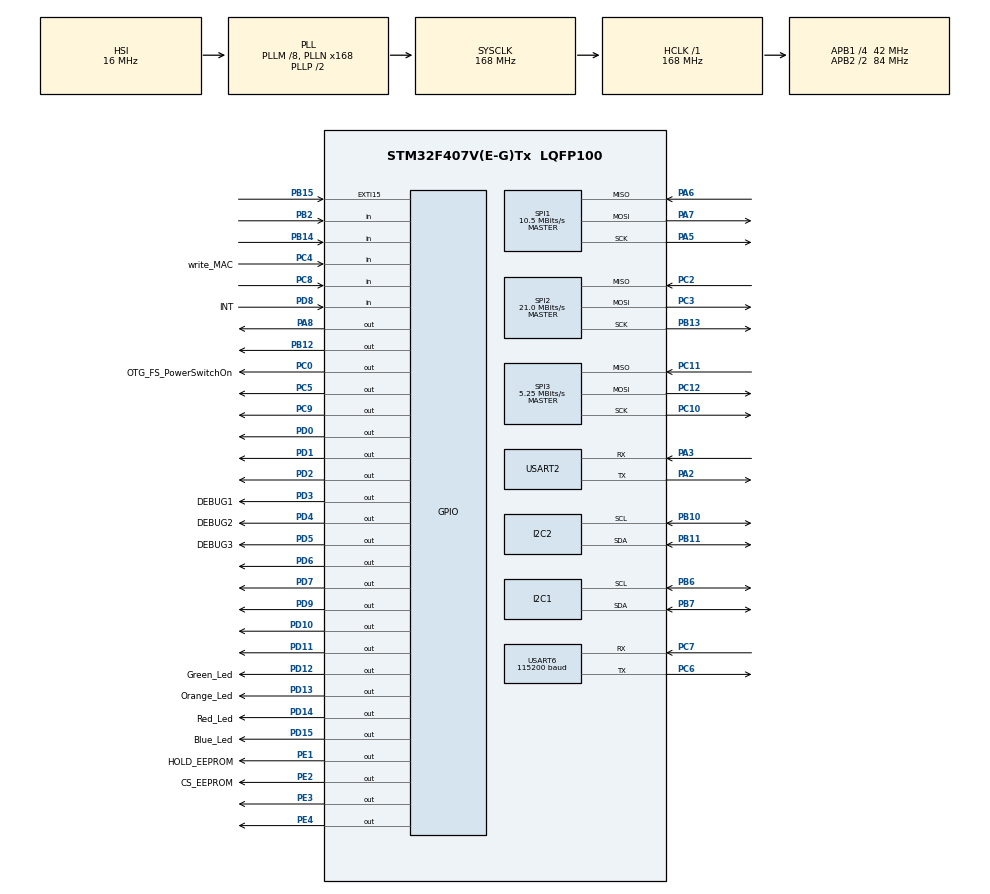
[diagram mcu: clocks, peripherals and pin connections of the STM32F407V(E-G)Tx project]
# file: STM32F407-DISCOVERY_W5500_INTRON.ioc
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Dma.Request0=USART6_TX
Dma.Request1=SPI1_TX
Dma.Request2=SPI1_RX
Dma.SPI1_RX.2.Direction=DMA_PERIPH_TO_MEMORY
Dma.SPI1_RX.2.FIFOMode=DMA_FIFOMODE_DISABLE
Dma.SPI1_RX.2.Instance=DMA2_Stream0
Dma.SPI1_RX.2.MemDataAlignment=DMA_MDATAALIGN_BYTE
Dma.SPI1_RX.2.MemInc=DMA_MINC_ENABLE
Dma.SPI1_RX.2.Mode=DMA_NORMAL
Dma.SPI1_RX.2.PeriphDataAlignment=DMA_PDATAALIGN_BYTE
Dma.SPI1_RX.2.PeriphInc=DMA_PINC_DISABLE
Dma.SPI1_RX.2.Priority=DMA_PRIORITY_LOW
Dma.SPI1_TX.1.Direction=DMA_MEMORY_TO_PERIPH
Dma.SPI1_TX.1.FIFOMode=DMA_FIFOMODE_DISABLE
Dma.SPI1_TX.1.Instance=DMA2_Stream3
Dma.SPI1_TX.1.MemDataAlignment=DMA_MDATAALIGN_BYTE
Dma.SPI1_TX.1.MemInc=DMA_MINC_ENABLE
Dma.SPI1_TX.1.Mode=DMA_NORMAL
Dma.SPI1_TX.1.PeriphDataAlignment=DMA_PDATAALIGN_BYTE
Dma.SPI1_TX.1.PeriphInc=DMA_PINC_DISABLE
Dma.SPI1_TX.1.Priority=DMA_PRIORITY_LOW
Dma.USART6_TX.0.Direction=DMA_MEMORY_TO_PERIPH
Dma.USART6_TX.0.FIFOMode=DMA_FIFOMODE_DISABLE
Dma.USART6_TX.0.Instance=DMA2_Stream6
Dma.USART6_TX.0.MemDataAlignment=DMA_MDATAALIGN_BYTE
Dma.USART6_TX.0.MemInc=DMA_MINC_ENABLE
Dma.USART6_TX.0.Mode=DMA_NORMAL
Dma.USART6_TX.0.PeriphDataAlignment=DMA_PDATAALIGN_BYTE
Dma.USART6_TX.0.PeriphInc=DMA_PINC_DISABLE
Dma.USART6_TX.0.Priority=DMA_PRIORITY_HIGH
FATFS._FS_EXFAT=1
FATFS._FS_NOFSINFO=3
FATFS._MAX_SS=4096
FATFS._MULTI_PARTITION=1
FATFS._USE_CHMOD=1
FATFS._USE_EXPAND=1
FATFS._USE_FIND=1
FATFS._USE_FORWARD=1
FATFS._USE_LABEL=1
FATFS._USE_LFN=1
FATFS._USE_TRIM=1
I2C1.DutyCycle=I2C_DUTYCYCLE_2
I2C1.I2C_Mode=I2C_Fast
IWDG.Prescaler=IWDG_PRESCALER_128
IWDG.Reload=2000
Mcu.Family=STM32F4
Mcu.Name=STM32F407V(E-G)Tx
Mcu.Package=LQFP100
NVIC.DMA2_Stream0_IRQn=true\:0\:0\:false\:false\:true\:true\:true
NVIC.DMA2_Stream3_IRQn=true\:0\:0\:false\:false\:true\:true\:true
NVIC.DMA2_Stream6_IRQn=true\:0\:0\:false\:false\:true\:false\:true
NVIC.EXTI15_10_IRQn=true\:0\:0\:false\:false\:true\:true\:true
NVIC.PriorityGroup=NVIC_PRIORITYGROUP_4
NVIC.SPI3_IRQn=true\:0\:0\:false\:false\:true\:true\:true
NVIC.USART2_IRQn=true\:0\:0\:false\:false\:true\:true\:true
NVIC.USART6_IRQn=true\:0\:0\:false\:false\:true\:true\:true
PA13.GPIO_Label=SWDIO
PA13.Mode=Serial_Wire
PA13.Signal=SYS_JTMS-SWDIO
PA14.GPIO_Label=SWCLK
PA14.Mode=Serial_Wire
PA14.Signal=SYS_JTCK-SWCLK
PA2.Mode=Asynchronous
PA2.Signal=USART2_TX
PA3.Mode=Asynchronous
PA3.Signal=USART2_RX
PA5.Mode=Full_Duplex_Master
PA5.Signal=SPI1_SCK
PA6.Mode=Full_Duplex_Master
PA6.Signal=SPI1_MISO
PA7.Mode=Full_Duplex_Master
PA7.Signal=SPI1_MOSI
PA8.GPIO_Speed=GPIO_SPEED_FREQ_VERY_HIGH
PA8.PinState=GPIO_PIN_SET
PA8.Signal=GPIO_Output
PB10.Mode=I2C
PB10.Signal=I2C2_SCL
PB11.Mode=I2C
PB11.Signal=I2C2_SDA
PB12.Signal=GPIO_Output
PB13.GPIO_PuPd=GPIO_PULLUP
PB13.Mode=Full_Duplex_Master
PB13.Signal=SPI2_SCK
PB14.GPIO_PuPd=GPIO_PULLDOWN
PB14.Signal=GPIO_Input
PB15.Signal=GPXTI15
PB2.Signal=GPIO_Input
PB6.Mode=I2C
PB6.Signal=I2C1_SCL
PB7.Mode=I2C
PB7.Signal=I2C1_SDA
PC0.GPIO_Label=OTG_FS_PowerSwitchOn
PC0.GPIO_PuPd=GPIO_NOPULL
PC0.GPIO_Speed=GPIO_SPEED_FREQ_LOW
PC0.PinState=GPIO_PIN_SET
PC0.Signal=GPIO_Output
PC10.GPIO_PuPd=GPIO_NOPULL
PC10.Mode=Full_Duplex_Master
PC10.Signal=SPI3_SCK
PC11.GPIO_PuPd=GPIO_PULLUP
PC11.Mode=Full_Duplex_Master
PC11.Signal=SPI3_MISO
PC12.GPIO_PuPd=GPIO_PULLUP
PC12.Mode=Full_Duplex_Master
PC12.Signal=SPI3_MOSI
PC2.GPIO_PuPd=GPIO_NOPULL
PC2.Mode=Full_Duplex_Master
PC2.Signal=SPI2_MISO
PC3.GPIO_PuPd=GPIO_PULLUP
PC3.Mode=Full_Duplex_Master
PC3.Signal=SPI2_MOSI
PC4.GPIO_Label=write_MAC
PC4.Signal=GPIO_Input
PC5.Signal=GPIO_Output
PC6.Mode=Asynchronous
PC6.Signal=USART6_TX
PC7.Mode=Asynchronous
PC7.Signal=USART6_RX
PC8.Signal=GPIO_Input
PC9.GPIO_Speed=GPIO_SPEED_FREQ_VERY_HIGH
PC9.PinState=GPIO_PIN_SET
PC9.Signal=GPIO_Output
PD0.GPIO_Speed=GPIO_SPEED_FREQ_VERY_HIGH
PD0.Signal=GPIO_Output
PD1.GPIO_Speed=GPIO_SPEED_FREQ_VERY_HIGH
PD1.Signal=GPIO_Output
PD10.GPIO_Speed=GPIO_SPEED_FREQ_VERY_HIGH
PD10.PinState=GPIO_PIN_RESET
PD10.Signal=GPIO_Output
PD11.GPIO_Speed=GPIO_SPEED_FREQ_VERY_HIGH
PD11.PinState=GPIO_PIN_SET
PD11.Signal=GPIO_Output
PD12.GPIO_Label=Green_Led
PD12.GPIO_PuPd=GPIO_NOPULL
PD12.GPIO_Speed=GPIO_SPEED_FREQ_VERY_HIGH
PD12.Signal=GPIO_Output
PD13.GPIO_Label=Orange_Led
PD13.GPIO_PuPd=GPIO_NOPULL
PD13.GPIO_Speed=GPIO_SPEED_FREQ_VERY_HIGH
PD13.Signal=GPIO_Output
PD14.GPIO_Label=Red_Led
PD14.GPIO_PuPd=GPIO_NOPULL
PD14.GPIO_Speed=GPIO_SPEED_FREQ_VERY_HIGH
PD14.Signal=GPIO_Output
PD15.GPIO_Label=Blue_Led
PD15.GPIO_PuPd=GPIO_NOPULL
PD15.GPIO_Speed=GPIO_SPEED_FREQ_VERY_HIGH
PD15.Signal=GPIO_Output
PD2.GPIO_PuPd=GPIO_PULLUP
PD2.GPIO_Speed=GPIO_SPEED_FREQ_MEDIUM
PD2.PinState=GPIO_PIN_SET
PD2.Signal=GPIO_Output
PD3.GPIO_Label=DEBUG1
PD3.GPIO_Speed=GPIO_SPEED_FREQ_VERY_HIGH
PD3.Signal=GPIO_Output
PD4.GPIO_Label=DEBUG2
PD4.GPIO_Speed=GPIO_SPEED_FREQ_VERY_HIGH
PD4.Signal=GPIO_Output
PD5.GPIO_Label=DEBUG3
PD5.GPIO_Speed=GPIO_SPEED_FREQ_VERY_HIGH
PD5.Signal=GPIO_Output
PD6.Signal=GPIO_Output
PD7.GPIO_Speed=GPIO_SPEED_FREQ_VERY_HIGH
PD7.Signal=GPIO_Output
PD8.GPIO_Label=INT
PD8.Signal=GPIO_Input
PD9.GPIO_Speed=GPIO_SPEED_FREQ_VERY_HIGH
PD9.Signal=GPIO_Output
PE1.GPIO_Label=HOLD_EEPROM
PE1.PinState=GPIO_PIN_SET
PE1.Signal=GPIO_Output
PE2.GPIO_Label=CS_EEPROM
PE2.GPIO_PuPd=GPIO_PULLUP
PE2.GPIO_Speed=GPIO_SPEED_FREQ_MEDIUM
PE2.PinState=GPIO_PIN_SET
PE2.Signal=GPIO_Output
PE3.Signal=GPIO_Output
PE4.Signal=GPIO_Output
PH0-OSC_IN.GPIO_Label=PH0-OSC_IN
PH0-OSC_IN.Mode=HSE-External-Oscillator
PH0-OSC_IN.Signal=RCC_OSC_IN
PH1-OSC_OUT.GPIO_Label=PH1-OSC_OUT
PH1-OSC_OUT.Mode=HSE-External-Oscillator
PH1-OSC_OUT.Signal=RCC_OSC_OUT
ProjectManager.HeapSize=0x2000
ProjectManager.StackSize=0x4000
ProjectManager.TargetToolchain=STM32CubeIDE
RCC.48MHZClocksFreq_Value=48000000
RCC.AHBFreq_Value=168000000
RCC.APB1CLKDivider=RCC_HCLK_DIV4
RCC.APB1Freq_Value=42000000
RCC.APB1TimFreq_Value=84000000
RCC.APB2CLKDivider=RCC_HCLK_DIV2
RCC.APB2Freq_Value=84000000
RCC.APB2TimFreq_Value=168000000
RCC.CortexFreq_Value=168000000
RCC.HCLKFreq_Value=168000000
RCC.HSE_VALUE=5000000
RCC.HSI_VALUE=16000000
RCC.LSE_VALUE=32768
RCC.PLLM=8
RCC.PLLN=168
RCC.PLLQ=7
RCC.SYSCLKFreq_VALUE=168000000
RCC.SYSCLKSource=RCC_SYSCLKSOURCE_PLLCLK
RCC.VCOOutputFreq_Value=336000000
RTC.Date=9
RTC.Month=RTC_MONTH_MAY
RTC.Year=23
SPI1.BaudRatePrescaler=SPI_BAUDRATEPRESCALER_8
SPI1.CalculateBaudRate=10.5 MBits/s
SPI1.Direction=SPI_DIRECTION_2LINES
SPI1.Mode=SPI_MODE_MASTER
SPI1.VirtualType=VM_MASTER
SPI2.BaudRatePrescaler=SPI_BAUDRATEPRESCALER_2
SPI2.CLKPhase=SPI_PHASE_2EDGE
SPI2.CLKPolarity=SPI_POLARITY_LOW
SPI2.CalculateBaudRate=21.0 MBits/s
SPI2.Direction=SPI_DIRECTION_2LINES
SPI2.Mode=SPI_MODE_MASTER
SPI2.VirtualType=VM_MASTER
SPI3.BaudRatePrescaler=SPI_BAUDRATEPRESCALER_8
SPI3.CLKPhase=SPI_PHASE_1EDGE
SPI3.CLKPolarity=SPI_POLARITY_LOW
SPI3.CRCCalculation=SPI_CRCCALCULATION_DISABLE
SPI3.CalculateBaudRate=5.25 MBits/s
SPI3.DataSize=SPI_DATASIZE_8BIT
SPI3.Direction=SPI_DIRECTION_2LINES
SPI3.Mode=SPI_MODE_MASTER
SPI3.VirtualType=VM_MASTER
USART2.VirtualMode=VM_ASYNC
USART6.BaudRate=115200
USART6.VirtualMode=VM_ASYNC
VP_CRC_VS_CRC.Mode=CRC_Activate
VP_FATFS_VS_Generic.Mode=User_defined
VP_IWDG_VS_IWDG.Mode=IWDG_Activate
VP_RNG_VS_RNG.Mode=RNG_Activate
VP_RTC_VS_RTC_Activate.Mode=RTC_Enabled
VP_RTC_VS_RTC_Calendar.Mode=RTC_Calendar
VP_wolfSSL.I-CUBE-wolfSSL_VS_wolfSSLJjwolfSSL_5.6.0_5.6.0.Mode=wolfSSLJjwolfSSL
board=STM32F407G-DISC1
wolfSSL.I-CUBE-wolfSSL.5.6.0.WOLF_CONF_MD5=1
wolfSSL.I-CUBE-wolfSSL.5.6.0.WOLF_CONF_WOLFCRYPT_ONLY=0
wolfSSL.I-CUBE-wolfSSL.5.6.0.wolfSSLCcwolfSSLJjwolfCryptJjCore=true
wolfSSL.I-CUBE-wolfSSL.5.6.0.wolfSSLCcwolfSSLJjwolfCryptJjTest=true
wolfSSL.I-CUBE-wolfSSL.5.6.0.wolfSSLCcwolfSSLJjwolfSSLJjCore=true

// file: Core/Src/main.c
/* USER CODE BEGIN Header */

#include "socket.h"
#include "w5500.h"
#include "net.h"
#include "loopback.h"
#include "wizchip_init.h"
//#include "SSLInterface.h"
#include "httpServer.h"
#include "webpage.h"
#include "spi_eeprom.h"
#include "eeprom.h"
#include "SEGGER_RTT.h"
#include "config.h"

/* USER CODE END Header */
#include "main.h"
#include "fatfs.h"

/* USER CODE BEGIN Includes */

#include "stdio.h"
#include "stdarg.h"
#include <string.h>
#include <stdlib.h>
#include <stdint.h>

/* USER CODE END Includes */

/* USER CODE BEGIN PD */

extern void FsForEeprom_test();
extern void littleFsInit();
extern int tls_client_serverTest();
extern void tls_server_Handshake();
extern void polarSSLTest();
extern void bearSSLTest();
#define I2C_REQUEST_WRITE                       0x00
#define I2C_REQUEST_READ                        0x01
#define SLAVE_OWN_ADDRESS                       0xA0
uint32_t count = 0;
uint8_t sdCartOn = 1;
char *pindex;
char *pmain;
char *psettingsIP;
uint8_t ABONENT_or_BASE;
uint8_t HANDSHAKE = hanshakeOFF;
uint8_t UDP_or_TCP = UDP;
int8_t numWait = 50; //Количество ожиданий в цикле Handshake
uint32_t num_send = 0;
uint32_t num_rcvd = 0;
uint32_t num_rcvd_SEGGER = 0;
uint32_t num_skip_packet = 0;
#ifdef enable_SKIP_Packets
uint8_t nextPacketSkip = 0;
#endif
uint8_t SEGGER = 0;
uint8_t NET_DIAGNOSTIC_BASE = 0;
uint8_t NET_DIAGNOSTIC_ABON = 0;
uint32_t numBadPackets2Channel = 0;
uint32_t numGoodPackets2Channel = 0;
uint32_t bridgeState = CONNECTION_NO;
uint32_t compareDataInChannelState = NO_ERRORS;
uint32_t startHttpTime = 0;
#ifdef LFS
extern lfs_t lfs;
extern lfs_file_t file;
#endif
#define WRITE_ONCE_TO_EEPROM 1024
uint16_t local_port_web = LOCAL_PORT_WEB;
uint16_t local_port_udp = LOCAL_PORT_UDP;
uint8_t destipHOST[4] = {192,168,1,11}; //для тестов

uint8_t loginState = loginOFF;
uint8_t passwordState = PasswordOFF;
uint8_t web = webON;
uint8_t setResetTwice = 0;
extern int8_t http_disconnect(uint8_t sn);

uint8_t CCMRAMDATA dataToBase[MAX_PACKET_LEN];     //Данные от абонента принятые по Ethernet
uint8_t CCMRAMDATA dataFromBase[MAX_PACKET_LEN];   //Данные для абонента к передаче по Ethernet
uint8_t CCMRAMDATA dataFromBase2[MAX_PACKET_LEN];
#ifdef enable_BUFFER_FIFO
char bufDataFromBase[MAX_PACKET_LEN * BUF_PACKET_SIZE]; //Буфер базы
char bufDataFromAbon[MAX_PACKET_LEN * BUF_PACKET_SIZE]; //Буфер абонента (не работает)
uint16_t CCMRAMDATA indexFpgaBufData = 0;
uint16_t CCMRAMDATA indexSendBufData = BUF_PACKET_SIZE/2;
#endif
uint8_t CCMRAMDATA dataToDx[MAX_PACKET_LEN];       //Данные от базы принятые по Ethernet
uint8_t CCMRAMDATA dataFromDx[MAX_PACKET_LEN];     //Данные для базы к передаче по Ethernet
uint8_t CCMRAMDATA receivedDataFrom_2_Channel[MAX_PACKET_LEN / 4];
uint8_t CCMRAMDATA trueDataFrom_2_Channel[MAX_PACKET_LEN / 4] = {0xEE, 0xEE, 0xEE, 0xEE, 0xEE, 0xEE, 0xEE, 0xEE, 0xEE, 0xEE, 0xEE, 0xEE};

#ifdef enable_smallBUFFER
uint8_t CCMRAMDATA smallBufDataToBase[MAX_PACKET_LEN * SMALL_BUFF_SIZE];
uint8_t smallBufDataToBaseIndex = SMALL_BUFF_SIZE;
uint8_t CCMRAMDATA smallBufDataFromBase[MAX_PACKET_LEN * SMALL_BUFF_SIZE];
uint8_t smallBufDataFromBaseIndex = 0;
uint8_t CCMRAMDATA smallBufDataToDx[MAX_PACKET_LEN * SMALL_BUFF_SIZE];
uint8_t smallBufDataToDxIndex = SMALL_BUFF_SIZE;
uint8_t CCMRAMDATA smallBufDataFromDx[MAX_PACKET_LEN * SMALL_BUFF_SIZE];
uint8_t smallBufDataFromDxIndex = 0;
#endif

FIRMWARESECTION char dataToNewSectionInFlash [10][4] = //В новой секции 10 ячеек по 32 бита
    {
        {main_FW},
        {patch_FW},
        {year_FW},
        {month_FW},
        {day_FW},
        {hour_FW},
        {minute_FW},
        {second_FW},
        {"    "},
        {"    "},
    };//Далее в коде делаем фиктивный вызов dataToNewSectionInFlash[0] = 8888

extern uint8_t commandfromBaseToAbonentReboot[MAX_PACKET_LEN];
extern uint8_t commandfromBaseToAbonentNetDiagnostic[MAX_PACKET_LEN];
extern uint8_t test1[MAX_PACKET_LEN];
extern uint8_t test2[MAX_PACKET_LEN];
extern uint8_t test3[MAX_PACKET_LEN];
extern uint8_t test4[MAX_PACKET_LEN];
extern uint8_t test5[MAX_PACKET_LEN];
extern uint8_t test6[MAX_PACKET_LEN];
extern uint8_t test7[MAX_PACKET_LEN];
extern uint8_t test8[MAX_PACKET_LEN];
extern uint8_t test9[MAX_PACKET_LEN];
extern uint8_t zeroStr[MAX_PACKET_LEN];

I2C_HandleTypeDef hi2c1;

IWDG_HandleTypeDef hiwdg;

RNG_HandleTypeDef hrng;

RTC_HandleTypeDef hrtc;

SPI_HandleTypeDef hspi1;
SPI_HandleTypeDef hspi2;
SPI_HandleTypeDef hspi3;

UART_HandleTypeDef huart2;
UART_HandleTypeDef huart6;
DMA_HandleTypeDef hdma_usart6_tx;
/* USER CODE END PD */

CRC_HandleTypeDef hcrc;

I2C_HandleTypeDef hi2c1;
I2C_HandleTypeDef hi2c2;

IWDG_HandleTypeDef hiwdg;

RNG_HandleTypeDef hrng;

RTC_HandleTypeDef hrtc;

SPI_HandleTypeDef hspi1;
SPI_HandleTypeDef hspi2;
SPI_HandleTypeDef hspi3;
DMA_HandleTypeDef hdma_spi1_tx;
DMA_HandleTypeDef hdma_spi1_rx;

UART_HandleTypeDef huart2;
UART_HandleTypeDef huart6;
DMA_HandleTypeDef hdma_usart6_tx;

/* USER CODE BEGIN PV */
extern uint8_t RxBuffer[256];
extern uint8_t EEPROM_StatusByte;

uint8_t TxBuffer[256] = "__12345COOL!!!1234512345qwertasdfgh";
uint8_t capture = 0;
uint8_t ipaddr[4];
uint8_t ipgate[4];
uint8_t ipmask[4];
char MD5[33];
#ifndef   NEW_HTTP_SERVER
uint32_t indexLen;
uint32_t mainLen;
#endif
uint8_t destip[4];
uint8_t macaddr[6]={0x00}/*MAC_ADDR*/;
extern wiz_NetInfo defaultNetInfo;
#define DATA_BUF_SIZE   2048
uint8_t CCMRAMDATA RX_BUF_WEB[DATA_BUF_SIZE];
uint8_t CCMRAMDATA TX_BUF_WEB[DATA_BUF_SIZE];
uint8_t socknumlist[] = {0, 1, 2, 3};
extern char host_IP[16]; //для http Сервера
extern char dest_IP[16];
extern char gate_IP[16];
extern char mask_IP[16];
extern char mac[18];
extern char version[6];
extern char mode[8];

FATFS fs;
FIL fil;
/* USER CODE END PV */

void SystemClock_Config(void);
static void MX_GPIO_Init(void);
static void MX_DMA_Init(void);
static void MX_USART6_UART_Init(void);
static void MX_SPI3_Init(void);
static void MX_SPI1_Init(void);
static void MX_SPI2_Init(void);
static void MX_RNG_Init(void);
static void MX_RTC_Init(void);
static void MX_I2C1_Init(void);
static void MX_USART2_UART_Init(void);
static void MX_IWDG_Init(void);
static void MX_CRC_Init(void);
static void MX_I2C2_Init(void);
/* USER CODE BEGIN PFP */
static void MX_IWDG_Init_abonent(void);
static void MX_IWDG_Init_base(void);
void testSpiEepromReadPage(uint32_t adr);
void printf_DMA(const char* fmt, ...);
extern void print_network_information(void);

void HAL_GPIO_EXTI_Callback(uint16_t GPIO_Pin)
{
    if(GPIO_Pin== GPIO_PIN_15) {

//        SEGGER_RTT_SetTerminal(5);
//        SEGGER_RTT_printf(0, "EXTI\r\n");
//        SEGGER_RTT_SetTerminal(0);
    } else{
        __NOP();
    }
}

//void HAL_TIM_PeriodElapsedCallback(TIM_HandleTypeDef *htim)
//{
//// Этот обратный вызов автоматически вызывается HAL при возникновении события UEV
//    if(htim->Instance == TIM1) //check if the interrupt comes from TIM1
//    {
//        ++capture;
//        HAL_GPIO_WritePin(GPIOD, GPIO_PIN_10, GPIO_PIN_SET);
//        HAL_GPIO_WritePin(GPIOD, GPIO_PIN_10, GPIO_PIN_RESET);

//        if (capture == 2)
//        {
//            ++count;
////            HAL_SPI_TransmitReceive(&hspi3, txBuf , rxBuf, MAX_PACKET_LEN, 0x1000);
////            memcpy(txBuf, rxBuf + 1, MAX_PACKET_LEN);
//        }
//        if (capture == 1)
//        {
//            HAL_GPIO_WritePin(GPIOD, GPIO_PIN_9, GPIO_PIN_SET);
//            HAL_GPIO_WritePin(GPIOD, GPIO_PIN_9, GPIO_PIN_RESET);

//        }
//    }

//}
void HAL_SPI_TxCpltCallback(SPI_HandleTypeDef *hspi)
{
    if(hspi->Instance == SPI3)
    {
//        HAL_GPIO_WritePin(GPIOD, GPIO_PIN_9, GPIO_PIN_SET);
//        HAL_GPIO_WritePin(GPIOD, GPIO_PIN_9, GPIO_PIN_RESET);
    }
}
void HAL_SPI_RxCpltCallback(SPI_HandleTypeDef *hspi)
{
//    if(hspi->Instance == SPI3)
//    {
//        HAL_GPIO_WritePin(GPIOD, GPIO_PIN_10, GPIO_PIN_SET);
//        HAL_GPIO_WritePin(GPIOD, GPIO_PIN_10, GPIO_PIN_RESET);
//    }
}

//void HAL_TIM_IC_CaptureCallback(TIM_HandleTypeDef *htim)
//{
//    capture = 0;
////    HAL_GPIO_WritePin(GPIOD, GPIO_PIN_9, GPIO_PIN_SET);
////    HAL_GPIO_WritePin(GPIOD, GPIO_PIN_9, GPIO_PIN_RESET);
//}

/* USER CODE END PFP */

/* USER CODE BEGIN 0 */

typedef enum {
    eepromCLEAR,
    eepromNotCLEAR
} isEEPROMClear;

typedef enum {
    eepromSPICLEAR,
    eepromSPINotCLEAR
} isSPIEEPROMClear;

isEEPROMClear isEEPROMclear(uint16_t Addr);
isSPIEEPROMClear isSPIEEPROMclear(uint16_t Addr);

void printFileFromEEPROM(const char* nameFile_onEEPROM);

void simpleTestI2C_EEPROM(uint16_t addr)
{
    uint16_t num = 256;
    printf("Simple test I2C_EEPROM ...\r\n");

    uint8_t rd_value[256] = {0};
    uint8_t wr_value[256] = {'1','2','3','4','5','6','7','8','9','a','b','c','d','e','f',
                             '1','2','3','4','5','6','7','8','9','a','b','c','d','e','f',
                             '1','2','3','4','5','6','7','8','9','a','b','c','d','e','f',
                             '1','2','3','4','5','6','7','8','9','a','b','c','d','e','f',
                             '1','2','3','4','5','6','7','8','9','a','b','c','d','e','f',
                             '1','2','3','4','5','6','7','8','9','a','b','c','d','e','f',
                             '1','2','3','4','5','6','7','8','9','a','b','c','d','e','f',
                             'Q','W','R','_','_','*',
                             '1','2','3','4','5','6','7','8','9','a','b','c','d','e','f','\0'};

    uint8_t wr_value2[256] = {'A','B','3','D','E','F','J','K','L','M','N','O','P','Q','R','\0'};
    BSP_EEPROM_ReadBuffer(rd_value, addr, &num);
    printf("EEPROM read: %s\r\n",rd_value);
    printf("EEPROM write:");
    printf("%s\r\n",wr_value);
    BSP_EEPROM_WriteBuffer(wr_value, addr, num);
    delayUS_ASM(100000);
    BSP_EEPROM_ReadBuffer(rd_value, addr, &num);
    printf("EEPROM read: %s\r\n",rd_value);
    delayUS_ASM(100000);

    printf("EEPROM write:");
    printf("%s\r\n",wr_value2);
    BSP_EEPROM_WriteBuffer(wr_value2, addr, num);
    delayUS_ASM(100000);
    BSP_EEPROM_ReadBuffer(rd_value, addr, &num);
    printf("EEPROM read: %s\r\n",rd_value);
    delayUS_ASM(100000);
    printf("Simple test I2C_EEPROM ..OK\r\n\n");

    uint16_t len = 93;
    uint8_t rd_value2[93] = {0};
    BSP_EEPROM_ReadBuffer(rd_value2, ipSettingAdressInEEPROM, &len);
    printf("\r\nEEPROM settings read: %s\r\n", rd_value2);

}

void saveLenFileToEeprom(const char* nameFile_onSD, uint32_t numByteFile)
{
    printf("save len file %s to eeprom\n", nameFile_onSD);
    const char* index = "index.html";
    const char* main = "main.html";
    char tmp[6];
    sprintf(tmp,"%.5d", numByteFile);
    if (nameFile_onSD == index)
    {
        BSP_EEPROM_WriteBuffer((uint8_t*)tmp, indexLenAdressInEEPROM, 6);
    }
    if (nameFile_onSD == main)
    {
        BSP_EEPROM_WriteBuffer((uint8_t*)tmp, mainLenAdressInEEPROM, 6);
    }
}

void copyFileToAdressEEPROM(const char* nameFile_onSD, uint16_t WriteAddr)
{
    printf("\n\nCopy file %s to adress 0x%.4X i2c eeprom \n",nameFile_onSD, WriteAddr);
    FRESULT result = f_open(&fil, nameFile_onSD, FA_OPEN_ALWAYS | FA_READ );
    if (result == FR_OK)
    {
        uint32_t numByteFile = fil.obj.objsize;
        saveLenFileToEeprom(nameFile_onSD, numByteFile);
        printf("num byte: %d\n",numByteFile);
        UINT rc;
        pindex = malloc(numByteFile);
        FRESULT res = f_read(&fil, pindex, numByteFile, &rc);
        printf("file %s read: %d\n", nameFile_onSD, res);
    //    printf("copy %s to eeprpm (adress 0x%.4X)\n", nameFile_onSD, WriteAddr);
        int result = BSP_EEPROM_WriteBuffer((uint8_t*)pindex, WriteAddr, numByteFile);
        printf("file %s write to adress 0x%.4X on eprom: %d\n", nameFile_onSD, WriteAddr, result);
        f_close(&fil);
        free (pindex);
    }
    else
    {
        printf("\nError opening file %s!!! \n",nameFile_onSD);
    }
}

void copyFileToEEPROM(const char* nameFile_onSD)
{
#ifdef LFS
    uint32_t time = HAL_GetTick();
    f_open(&fil, nameFile_onSD, FA_OPEN_ALWAYS | FA_READ );
    uint32_t numByteFile = fil.obj.objsize;
    UINT rc;
    pindex = malloc(numByteFile);
    f_read(&fil, pindex, numByteFile, &rc);
    f_close(&fil);

    printf("copy %s ... ", nameFile_onSD);
    lfs_file_open(&lfs, &file, nameFile_onSD, LFS_O_WRONLY | LFS_O_CREAT );
    lfs_file_write(&lfs, &file, pindex, numByteFile);
    lfs_file_close(&lfs, &file);
    memset(pindex, 0x00, numByteFile);
    free (pindex);
    char tmp[30];
    sprintf(tmp,"%ds\n", (HAL_GetTick() - time)/1000 );
    Printf(tmp);
//    printFileFromEEPROM(nameFile_onSD);
#endif
}

void loadFilesFromEepromToMemory(uint16_t ReadAddrIndex, uint16_t numByteFileIndex,
                                 uint16_t ReadAddrMain, uint16_t numByteFileMain,
                                 uint16_t ReadAddrSettings, uint16_t numByteFileSettings )
{
    printf("load to memory index.html main.html ip_settings\n");
    uint16_t * numByteIndex = &numByteFileIndex;
    pindex = malloc(numByteFileIndex);
    int result = BSP_EEPROM_ReadBuffer((uint8_t*)pindex, ReadAddrIndex, numByteIndex);
//    printf("\nread %d byte from adress 0x%.4X on eprom: %d\n", numByteFileIndex, ReadAddrIndex, result);

    uint16_t * numByteMain = &numByteFileMain;
    pmain = malloc(numByteFileMain);
    result = BSP_EEPROM_ReadBuffer((uint8_t*)pmain, ReadAddrMain, numByteMain);
//    printf("read %d byte from adress 0x%.4X on eprom: %d\n", numByteFileMain, ReadAddrMain, result);

    //Тут гружу в память настройки
    uint16_t * numByteSettings = &numByteFileSettings;
    psettingsIP = malloc(numByteFileSettings);
    result = BSP_EEPROM_ReadBuffer((uint8_t*)psettingsIP, ReadAddrSettings, numByteSettings);
//    printf("read %d byte from adress 0x%.4X on eprom: %d\n", numByteFileSettings, ReadAddrSettings, result);
}

void printFilesFromMemory()
{
#ifndef   NEW_HTTP_SERVER
    Printf("\nprintFilesFromMemory\n\n");
        for (int i = 0; i < indexLen; ++i)
        {
            Printf("%c", pindex[i]);
        }
        Printf("\n\n\n");

        for (int i = 0; i < mainLen; ++i)
        {
            Printf("%c", pmain[i]);
        }
        Printf("\n");
#endif
}

void printFileFromAdressEEPROM(uint16_t ReadAddr, uint16_t numByteFile)
{
    printf("Print %d byte from 0x%.4X adress i2c eeprom\n",numByteFile, ReadAddr);
    uint16_t * numByte = &numByteFile;
    pindex = malloc(numByteFile);
    memset(pindex, 0x00, numByteFile);
    int result = BSP_EEPROM_ReadBuffer((uint8_t*)pindex, ReadAddr, numByte);
    printf("read %d byte from adress 0x%.4X on eprom: %d\n", numByteFile, ReadAddr, result);
    Printf("print reading file\n");
    for (int i = 0; i < numByteFile; ++i)
    {
        Printf("%c", pindex[i]);
    }
    Printf("\n");
    free (pindex);
}

void printFileFromEEPROM(const char* nameFile_onEEPROM)
{
#ifdef LFS
    lfs_file_open(&lfs, &file, nameFile_onEEPROM, LFS_O_RDONLY );
    uint32_t numByteFile = lfs_file_size(&lfs, &file);
    pindex = malloc(numByteFile);
    lfs_file_read(&lfs, &file, pindex, numByteFile);
    lfs_file_close(&lfs, &file);

    Printf("print %s\n", nameFile_onEEPROM);
    for (int i = 0; i < numByteFile; ++i)
    {
        Printf("%c", pindex[i]);
    }
    Printf("\n");
    free (pindex);
#endif
}

void testReadFile(const char* nameFile_onEEPROM)
{
#ifdef LFS
    printf_DMA("test read %s ... ", nameFile_onEEPROM); delayUS_ASM(1000);
    uint32_t time = HAL_GetTick();
    lfs_file_open(&lfs, &file, nameFile_onEEPROM, LFS_O_RDONLY );
    uint32_t numByteFile = lfs_file_size(&lfs, &file);
    pindex = malloc(numByteFile);
    lfs_file_read(&lfs, &file, pindex, numByteFile);
    lfs_file_close(&lfs, &file);
    free (pindex);
    char tmp[30];
    sprintf(tmp,"%ds\n", (HAL_GetTick() - time)/1000 );
    printf_DMA(tmp); delayUS_ASM(5000);
#endif
}

void markEEPROMasOld()
{
    char old[16] = {0x00,0xff,0xff,0xff,0xff,0xff,0xff,0xff,0xff,0xff,0xff,0xff,0xff,0xff,0xff,0x00};
    BSP_EEPROM_WriteBuffer((uint8_t*)old, markEEPROMclear, 16);
    printf("eeprom mark as OLD\n");
}

void markEEPROMasNew()
{
    char clear[16] = {0xff,0xff,0xff,0xff,0xff,0xff,0xff,0xff,0xff,0xff,0xff,0xff,0xff,0xff,0xff,0x00};
    //Ручная Установка признака новая
    BSP_EEPROM_WriteBuffer((uint8_t*)clear, markEEPROMclear, 16);
    printf("eeprom mark as NEW\n");
}

isEEPROMClear isEEPROMclear(uint16_t Addr)
{
    uint16_t numByte = 16;
    uint16_t * pnumByte = &numByte;
    char tmp[16];
    char clear[16] = {0xff,0xff,0xff,0xff,0xff,0xff,0xff,0xff,0xff,0xff,0xff,0xff,0xff,0xff,0xff,0x00};
    BSP_EEPROM_ReadBuffer((uint8_t *)tmp, Addr, pnumByte);
    if(strncmp(tmp, clear, 15) == 0)
        return eepromCLEAR;
    else
        return eepromNotCLEAR;
}

void copyMacToAdressEEPROM(uint16_t Addr)
{
#ifndef  MAC_IN_DECIMAL
    char tmp[18];
    FRESULT result = f_open(&fil, "mac16", FA_OPEN_ALWAYS | FA_READ );
    if (result == FR_OK)
    {
        printf("\nCopy MAC adress from SD in Hex to adress 0x%.4X eeprom\r\n",Addr);
        UINT rc;
        f_read(&fil, tmp, 18, &rc);
        f_close(&fil);
        tmp[17]=0x00;
        printf("MAC: %s\r\n",tmp);
        int open = BSP_EEPROM_WriteBuffer((uint8_t *)tmp, Addr, 18);
        printf("MAC write from SD in Hex to adress 0x%.4X on eprom: %d\r\n", Addr, open);
    }
#endif
#ifdef  MAC_IN_DECIMAL
    char tmp[24];
    FRESULT result = f_open(&fil, "mac10", FA_OPEN_ALWAYS | FA_READ );
    if (result == FR_OK)
    {
        printf("\nCopy MAC adress from SD in Decimal to adress 0x%.4X eeprom\n",Addr);
        UINT rc;
        f_read(&fil, tmp, 24, &rc);
        f_close(&fil);
        tmp[23]=0x00;
        printf("MAC:\n%s\n",tmp);
        int open = BSP_EEPROM_WriteBuffer((uint8_t *)tmp, Addr, 24);
        printf("MAC write from SD in Decimal to adress 0x%.4X on eprom: %d\n", Addr, open);
    }
#endif
}

void copyParametersFromSDToAdressEEPROM(uint16_t Addr)
{
    printf("\nCopy IP settings from SD to adress 0x%.4X eeprom\r\n",Addr);
    char tmp[settingsLen];
    f_open(&fil, "host_IP", FA_OPEN_ALWAYS | FA_READ );
    UINT rc;
    f_read(&fil, tmp, 15, &rc);
    f_close(&fil);
    f_open(&fil, "dest_IP", FA_OPEN_ALWAYS | FA_READ );
    f_read(&fil, tmp+15, 15, &rc);
    f_close(&fil);
    f_open(&fil, "gate_IP", FA_OPEN_ALWAYS | FA_READ );
    f_read(&fil, tmp+30, 15, &rc);
    f_close(&fil);
    f_open(&fil, "mask_IP", FA_OPEN_ALWAYS | FA_READ );
    f_read(&fil, tmp+45, 15, &rc);
    f_close(&fil);
    f_open(&fil, "md5", FA_OPEN_ALWAYS | FA_READ );
    f_gets(tmp+60, 33, &fil);
    f_close(&fil);
//    printf("settings: \t\t%s\r\n",tmp);
    BSP_EEPROM_WriteBuffer((uint8_t *)tmp, Addr, settingsLen);
    delayUS_ASM(100000);
//    Printf("Settings IP write to adress 0x%.4X on eprom: %d", Addr, result);

    uint16_t len = 93;
    uint8_t rd_value[93] = {0};
    BSP_EEPROM_ReadBuffer(rd_value, ipSettingAdressInEEPROM, &len);
    printf("\rEEPROM read settings:\t%s\r\n",rd_value);

}

void copyDefaultParametersToAdressSPIEEPROM(uint16_t Addr){
//    printf("copyDefaultParametersToAdressSPIEEPROM 0x%.4X \r\n",Addr);
    if (ABONENT_or_BASE == BASE) {
        char defaultIP[settingsLenInSPI] =
        {'1','9','2','.','1','6','8','.','0','0','1','.','1','2','2',
         '1','9','2','.','1','6','8','.','0','0','1','.','1','0','0',
         '1','9','2','.','1','6','8','.','0','0','1','.','0','0','1',
         '2','5','5','.','2','5','5','.','2','5','5','.','0','0','0',
         'd','4','1','d','8','c','d','9','8','f','0','0','b','2','0','4','e','9','8','0','0','9','9','8','e','c','f','8','4','2','7','e','\0'};
//        printf("default settings: %s\r\n",defaultIP);
        EEPROM_SPI_WriteBuffer((uint8_t *)defaultIP, Addr, settingsLenInSPI);
    } else {//Абонент
        char defaultIP[settingsLenInSPI] =
        {'1','9','2','.','1','6','8','.','0','0','1','.','1','0','0',
         '1','9','2','.','1','6','8','.','0','0','1','.','1','2','2',
         '1','9','2','.','1','6','8','.','0','0','1','.','0','0','1',
         '2','5','5','.','2','5','5','.','2','5','5','.','0','0','0',
         'd','4','1','d','8','c','d','9','8','f','0','0','b','2','0','4','e','9','8','0','0','9','9','8','e','c','f','8','4','2','7','e','\0'};
//        printf("default settings: %s\r\n",defaultIP);
        EEPROM_SPI_WriteBuffer((uint8_t *)defaultIP, Addr, settingsLenInSPI);
    }
}

void copyParametersFromSDToAdressSPIEEPROM(uint16_t Addr){
    printf("\nCopy IP settings from SD to adress 0x%.4X SPI eeprom\r\n",Addr);
    char tmp[settingsLenInSPI];
    f_open(&fil, "host_IP", FA_OPEN_ALWAYS | FA_READ );
    UINT rc;
    f_read(&fil, tmp, 15, &rc);
    f_close(&fil);
    f_open(&fil, "dest_IP", FA_OPEN_ALWAYS | FA_READ );
    f_read(&fil, tmp+15, 15, &rc);
    f_close(&fil);
    f_open(&fil, "gate_IP", FA_OPEN_ALWAYS | FA_READ );
    f_read(&fil, tmp+30, 15, &rc);
    f_close(&fil);
    f_open(&fil, "mask_IP", FA_OPEN_ALWAYS | FA_READ );
    f_read(&fil, tmp+45, 15, &rc);
    f_close(&fil);
    f_open(&fil, "md5", FA_OPEN_ALWAYS | FA_READ );
    f_gets(tmp+60, 33, &fil);
    f_close(&fil);
    printf("settings: \t\t%s\r\n",tmp);
    EEPROM_SPI_WriteBuffer((uint8_t *)tmp, Addr, settingsLenInSPI);
}

void copyDefaultMACToAdressSPIEEPROM(uint16_t Addr){ //только 16 - ричный
    printf("copyDefaultMACToAdressSPIEEPROM 0x%.4X \r\n",Addr);
    if (ABONENT_or_BASE == BASE) {
        char defaultMAC[18] =
        {'0','0',':','1','5',':','4','2',':','B','F',':','F','0',':','5','2','\0'};
        printf("default MAC: %s\r\n",defaultMAC);
        EEPROM_SPI_WriteBuffer((uint8_t *)defaultMAC, Addr, 18);
    } else {//абонент
        char defaultMAC[18] =
        {'0','0',':','1','5',':','4','2',':','B','F',':','F','0',':','5','3','\0'};
        printf("default MAC: %s\r\n",defaultMAC);
        EEPROM_SPI_WriteBuffer((uint8_t *)defaultMAC, Addr, 18);
    }
}

void copyMacToAdressSPIEEPROM(uint16_t Addr){
    printf("copyMacToAdressSPIEEPROM 0x%.4X \r\n",Addr);
    char tmp[18];
    FRESULT result = f_open(&fil, "mac16", FA_OPEN_ALWAYS | FA_READ );
    if (result == FR_OK)
    {
        printf("\nCopy MAC adress from SD in Hex to adress 0x%.4X eeprom\r\n",Addr);
        UINT rc;
        f_read(&fil, tmp, 18, &rc);
        f_close(&fil);
        tmp[17]=0x00;
        printf("MAC: %s\r\n",tmp);
        EEPROM_SPI_WriteBuffer((uint8_t *)tmp, Addr, 18);
        printf("MAC write from SD in Hex to adress 0x%.4X on SPI eprom\r\n", Addr);
    }

}

void  SetParaametersFromAdressSPIEEPROM(uint16_t Addr){
//    printf("Set IP settings from adress 0x%.4X SPIeeprom\r\n", Addr);

    char tmp[settingsLenInSPI];
    char tmp2[3];

    EEPROM_SPI_ReadBuffer((uint8_t *)tmp, Addr, settingsLenInSPI);
//    printf("settings: %.93s\r\n",tmp);

    strncpy(host_IP,tmp,15);
    strncpy(dest_IP,tmp+15,15);
    strncpy(gate_IP,tmp+30,15);
    strncpy(mask_IP,tmp+45,15);

    strncpy(tmp2,tmp,3);
    ipaddr[0] = atoi(tmp2);
    strncpy(tmp2,tmp+4,3);
    ipaddr[1] = atoi(tmp2);
    strncpy(tmp2,tmp+8,3);
    ipaddr[2] = atoi(tmp2);
    strncpy(tmp2,tmp+12,3);
    ipaddr[3] = atoi(tmp2);

    strncpy(tmp2,tmp+15,3);
    destip[0] = atoi(tmp2);
    strncpy(tmp2,tmp+19,3);
    destip[1] = atoi(tmp2);
    strncpy(tmp2,tmp+23,3);
    destip[2] = atoi(tmp2);
    strncpy(tmp2,tmp+27,3);
    destip[3] = atoi(tmp2);

    strncpy(tmp2,tmp+30,3);
    ipgate[0] = atoi(tmp2);
    strncpy(tmp2,tmp+34,3);
    ipgate[1] = atoi(tmp2);
    strncpy(tmp2,tmp+38,3);
    ipgate[2] = atoi(tmp2);
    strncpy(tmp2,tmp+42,3);
    ipgate[3] = atoi(tmp2);

    strncpy(tmp2,tmp+45,3);
    ipmask[0] = atoi(tmp2);
    strncpy(tmp2,tmp+49,3);
    ipmask[1] = atoi(tmp2);
    strncpy(tmp2,tmp+53,3);
    ipmask[2] = atoi(tmp2);
    strncpy(tmp2,tmp+57,3);
    ipmask[3] = atoi(tmp2);

    strncpy(MD5, tmp+60, 32);

    printf("host_IP: %d.%d.%d.%d\r\n",ipaddr[0],ipaddr[1],ipaddr[2],ipaddr[3]);
    printf("dest_IP: %d.%d.%d.%d\r\n",destip[0],destip[1],destip[2],destip[3]);
    printf("gate_IP: %d.%d.%d.%d\r\n",ipgate[0],ipgate[1],ipgate[2],ipgate[3]);
    printf("mask_IP: %d.%d.%d.%d\r\n",ipmask[0],ipmask[1],ipmask[2],ipmask[3]);
//    printf("md5: %.32s\r\n", MD5);
}

void  SetMacFromAdressSPIEEPROM(uint16_t Addr){
    printf("Set MAC adress in HEX from adress SPI eeprom 0x%.4X \r\n", Addr);
    char tmp[18];
    char tmp2[2];
    EEPROM_SPI_ReadBuffer((uint8_t *)tmp, Addr, 18);
    strncpy(mac,tmp,18);
    strncpy(tmp2, tmp, 2);
    macaddr[0] = convertHexToDecimal(tmp2);
    strncpy(tmp2,tmp+3, 2);
    macaddr[1] = convertHexToDecimal(tmp2);
    strncpy(tmp2,tmp+6, 2);
    macaddr[2] = convertHexToDecimal(tmp2);
    strncpy(tmp2,tmp+9, 2);
    macaddr[3] = convertHexToDecimal(tmp2);
    strncpy(tmp2,tmp+12, 2);
    macaddr[4] = convertHexToDecimal(tmp2);
    strncpy(tmp2,tmp+15, 2);
    macaddr[5] = convertHexToDecimal(tmp2);
    printf("mac: %.2X:%.2X:%.2X:%.2X:%.2X:%.2X\r\n",macaddr[0],macaddr[1],macaddr[2],macaddr[3],macaddr[4],macaddr[5]);
}

void  markSPIEEPROMasNew(uint16_t Addr){
    printf("markSPIEEPROMasNew \r\n");
    uint16_t numByte = 16;
    char markNEW[16] = {0xff,0xff,0xff,0xff,0xff,0xff,0xff,0xff,0xff,0xff,0xff,0xff,0xff,0xff,0xff,0xff};
    EEPROM_SPI_WriteBuffer((uint8_t *)markNEW, Addr, numByte);

}

void markSPIEEPROMasOld(uint16_t Addr){
    printf("markSPIEEPROMasOld \r\n");
    uint16_t numByte = 16;
    char markOLD[16] = {0x08,0x08,0x08,0x08,0x08,0x08,0x08,0x08,0x08,0x08,0x08,0x08,0x08,0x08,0x08,0x00};
    EEPROM_SPI_WriteBuffer((uint8_t *)markOLD, Addr, numByte);
}

isSPIEEPROMClear isSPIEEPROMclear(uint16_t Addr)
{
    uint16_t numByte = 16;
    char RxBuffer[16] = {0x00};
    char clear[16] = {0xff,0xff,0xff,0xff,0xff,0xff,0xff,0xff,0xff,0xff,0xff,0xff,0xff,0xff,0xff,0x00};
    EEPROM_SPI_ReadBuffer((uint8_t *)RxBuffer, Addr, numByte);
//    printf("adress 0x%X read: %.16s\r\n", Addr, RxBuffer);
    if(strncmp(RxBuffer, clear, 15) == 0)
        return eepromSPICLEAR;
    else
        return eepromSPINotCLEAR;
}

void copyDefaultParametersToAdressEEPROM(uint16_t Addr)
{
    printf("\nSet default IP settings to adress 0x%.4X eeprom\n",Addr);
    char defaultIP[settingsLen] =
    {'1','9','2','.','1','6','8','.','0','0','1','.','2','2','2',
     '1','9','2','.','1','6','8','.','0','0','1','.','2','0','0',
     '1','9','2','.','1','6','8','.','0','0','1','.','0','0','1',
     '2','5','5','.','2','5','5','.','2','5','5','.','0','0','0',
     'd','4','1','d','8','c','d','9','8','f','0','0','b','2','0','4','e','9','8','0','0','9','9','8','e','c','f','8','4','2','7','e'};
    printf("default settings:\n%s\n",defaultIP);
    int result = BSP_EEPROM_WriteBuffer((uint8_t *)defaultIP, Addr, settingsLen);
    Printf("Settings IP write to adress 0x%.4X on eprom: %d", Addr, result);
}

void copyDefaultMACToAdressEEPROM(uint16_t Addr)
{
    printf("Set default MAC adress to adress eeprom 0x%.4X \r\n", Addr);
    char defaultMAC[24] =
    {'0','0','0',':','0','2','1',':','0','6','6',':','1','9','1',':','2','4','0',':','0','8','2','\0'};
    int result = BSP_EEPROM_WriteBuffer((uint8_t *)defaultMAC, Addr, 24);
    printf("Set default MAC adress to adress eeprom 0x%.4X: %d\r\n", Addr, result);
}

void SetMacFromAdressEEPROM(uint16_t Addr)
{
#ifndef MAC_IN_DECIMAL
//    printf("Set mac from adress 0x%.4X I2Ceeprom  \r\n", Addr);
    uint16_t numByte = 18;
    uint16_t * pnumByte = &numByte;
    char tmp[18];
    char tmp2[2];
    BSP_EEPROM_ReadBuffer((uint8_t *)tmp, Addr, pnumByte);
//    printf("MAC: %s\r\n",tmp);
    strncpy(mac,tmp,18);
    strncpy(tmp2, tmp, 2);
    macaddr[0] = convertHexToDecimal(tmp2);
    strncpy(tmp2,tmp+3, 2);
    macaddr[1] = convertHexToDecimal(tmp2);
    strncpy(tmp2,tmp+6, 2);
    macaddr[2] = convertHexToDecimal(tmp2);
    strncpy(tmp2,tmp+9, 2);
    macaddr[3] = convertHexToDecimal(tmp2);
    strncpy(tmp2,tmp+12, 2);
    macaddr[4] = convertHexToDecimal(tmp2);
    strncpy(tmp2,tmp+15, 2);
    macaddr[5] = convertHexToDecimal(tmp2);
    printf("mac: %.2X:%.2X:%.2X:%.2X:%.2X:%.2X\r\n",macaddr[0],macaddr[1],macaddr[2],macaddr[3],macaddr[4],macaddr[5]);
#endif
#ifdef MAC_IN_DECIMAL
    printf("Set MAC adress in decimal from adress eeprom 0x%.4X \n", Addr);
    uint16_t numByte = 24;
    uint16_t * pnumByte = &numByte;
    char tmp[24];
    char tmp2[3];
    BSP_EEPROM_ReadBuffer((uint8_t *)tmp, Addr, pnumByte);
    printf("MAC: %s\n",tmp);
    strncpy(tmp2, tmp, 4);
    macaddr[0] = atoi(tmp2);
    strncpy(tmp2,tmp+4, 4);
    macaddr[1] = atoi(tmp2);
    strncpy(tmp2,tmp+8, 4);
    macaddr[2] = atoi(tmp2);
    strncpy(tmp2,tmp+12, 4);
    macaddr[3] = atoi(tmp2);
    strncpy(tmp2,tmp+16, 4);
    macaddr[4] = atoi(tmp2);
    strncpy(tmp2,tmp+20, 4);
    macaddr[5] = atoi(tmp2);
    printf("mac: %.2X:%.2X:%.2X:%.2X:%.2X:%.2X\n",macaddr[0],macaddr[1],macaddr[2],macaddr[3],macaddr[4],macaddr[5]);
#endif
}

void SetParaametersFromAdressEEPROM(uint16_t Addr)
{
    printf("Set IP paraameters from adress eeprom 0x%.4X \r\n", Addr);
    uint16_t numByte = settingsLen;
    uint16_t * pnumByte = &numByte;
    char tmp[settingsLen];
    char tmp2[3];

    int result = BSP_EEPROM_ReadBuffer((uint8_t *)tmp, Addr, pnumByte);
    printf("Settings IP read from adress 0x%.4X on eprom: %d\r\n", Addr, result);
    printf("settings: %.93s\r\n",tmp);

    strncpy(host_IP,tmp,15);
    strncpy(dest_IP,tmp+15,15);
    strncpy(gate_IP,tmp+30,15);
    strncpy(mask_IP,tmp+45,15);

    strncpy(tmp2,tmp,3);
    ipaddr[0] = atoi(tmp2);
    strncpy(tmp2,tmp+4,3);
    ipaddr[1] = atoi(tmp2);
    strncpy(tmp2,tmp+8,3);
    ipaddr[2] = atoi(tmp2);
    strncpy(tmp2,tmp+12,3);
    ipaddr[3] = atoi(tmp2);

    strncpy(tmp2,tmp+15,3);
    destip[0] = atoi(tmp2);
    strncpy(tmp2,tmp+19,3);
    destip[1] = atoi(tmp2);
    strncpy(tmp2,tmp+23,3);
    destip[2] = atoi(tmp2);
    strncpy(tmp2,tmp+27,3);
    destip[3] = atoi(tmp2);

    strncpy(tmp2,tmp+30,3);
    ipgate[0] = atoi(tmp2);
    strncpy(tmp2,tmp+34,3);
    ipgate[1] = atoi(tmp2);
    strncpy(tmp2,tmp+38,3);
    ipgate[2] = atoi(tmp2);
    strncpy(tmp2,tmp+42,3);
    ipgate[3] = atoi(tmp2);

    strncpy(tmp2,tmp+45,3);
    ipmask[0] = atoi(tmp2);
    strncpy(tmp2,tmp+49,3);
    ipmask[1] = atoi(tmp2);
    strncpy(tmp2,tmp+53,3);
    ipmask[2] = atoi(tmp2);
    strncpy(tmp2,tmp+57,3);
    ipmask[3] = atoi(tmp2);

    strncpy(MD5, tmp+60, 32);

    printf("host_IP: %d.%d.%d.%d\r\n",ipaddr[0],ipaddr[1],ipaddr[2],ipaddr[3]);
    printf("dest_IP: %d.%d.%d.%d\r\n",destip[0],destip[1],destip[2],destip[3]);
    printf("gate_IP: %d.%d.%d.%d\r\n",ipgate[0],ipgate[1],ipgate[2],ipgate[3]);
    printf("mask_IP: %d.%d.%d.%d\r\n",ipmask[0],ipmask[1],ipmask[2],ipmask[3]);
    printf("md5: %.16s\r\n", MD5);
}

void copyParametersToEEPROM()
{
#ifdef LFS
    Printf("\nCopy IP settings from SD to eeprom\n");
    char tmp[100];
    char tmp1[5];
    char tmp2[5];
    char tmp3[5];
    char tmp4[5];
    f_open(&fil, "host_IP", FA_OPEN_ALWAYS | FA_READ );
    f_gets(tmp1, 5, &fil);
    f_gets(tmp2, 5, &fil);
    f_gets(tmp3, 5, &fil);
    f_gets(tmp4, 5, &fil);
    f_close(&fil);
    sprintf(tmp,"%.3s\r\n%.3s\r\n%.3s\r\n%.3s\r\n",tmp1,tmp2,tmp3,tmp4);
    Printf("host_IP:\n%s\n", tmp);
    lfs_file_open(&lfs, &file, "host_IP", LFS_O_WRONLY | LFS_O_CREAT);
    lfs_file_write(&lfs, &file, &tmp, sizeof(tmp));
    lfs_file_close(&lfs, &file);

    f_open(&fil, "dest_IP", FA_OPEN_ALWAYS | FA_READ );
    f_gets(tmp1, 100, &fil);
    f_gets(tmp2, 100, &fil);
    f_gets(tmp3, 100, &fil);
    f_gets(tmp4, 100, &fil);
    f_close(&fil);
    sprintf(tmp,"%.3s\r\n%.3s\r\n%.3s\r\n%.3s\r\n",tmp1,tmp2,tmp3,tmp4);
    Printf("dest_IP:\n%s\n", tmp);
    lfs_file_open(&lfs, &file, "dest_IP", LFS_O_WRONLY | LFS_O_CREAT);
    lfs_file_write(&lfs, &file, &tmp, sizeof(tmp));
    lfs_file_close(&lfs, &file);

    f_open(&fil, "gate_IP", FA_OPEN_ALWAYS | FA_READ );
    f_gets(tmp1, 100, &fil);
    f_gets(tmp2, 100, &fil);
    f_gets(tmp3, 100, &fil);
    f_gets(tmp4, 100, &fil);
    f_close(&fil);
    sprintf(tmp,"%.3s\r\n%.3s\r\n%.3s\r\n%.3s\r\n",tmp1,tmp2,tmp3,tmp4);
    Printf("gate_IP:\n%s\n", tmp);
    lfs_file_open(&lfs, &file, "gate_IP", LFS_O_WRONLY | LFS_O_CREAT);
    lfs_file_write(&lfs, &file, &tmp, sizeof(tmp));
    lfs_file_close(&lfs, &file);

    f_open(&fil, "mask_IP", FA_OPEN_ALWAYS | FA_READ );
    f_gets(tmp1, 100, &fil);
    f_gets(tmp2, 100, &fil);
    f_gets(tmp3, 100, &fil);
    f_gets(tmp4, 100, &fil);
    f_close(&fil);
    sprintf(tmp,"%.3s\r\n%.3s\r\n%.3s\r\n%.3s\r\n",tmp1,tmp2,tmp3,tmp4);
    Printf("mask_IP:\n%s\n", tmp);
    lfs_file_open(&lfs, &file, "mask_IP", LFS_O_WRONLY | LFS_O_CREAT);
    lfs_file_write(&lfs, &file, &tmp, sizeof(tmp));
    lfs_file_close(&lfs, &file);

    f_open(&fil, "md5", FA_OPEN_ALWAYS | FA_READ );
    f_gets(tmp, 100, &fil);
    strncpy(MD5, tmp, 32);
    f_close(&fil);
    lfs_file_open(&lfs, &file, "md5", LFS_O_WRONLY | LFS_O_CREAT);
    lfs_file_write(&lfs, &file, &tmp, sizeof(tmp));
    lfs_file_close(&lfs, &file);
#endif
}

void setMacFromSD()
{
#ifndef  MAC_IN_DECIMAL
    char tmp[18];
    char tmp2[2];
    f_open(&fil, "mac16", FA_OPEN_ALWAYS | FA_READ );
    f_lseek(&fil, 0);
    f_gets(tmp, 18, &fil);
    strncpy(mac,tmp,18);
    strncpy(tmp2,tmp,2);
    macaddr[0] = convertHexToDecimal(tmp2);
    strncpy(tmp2,tmp+3,2);
    macaddr[1] = convertHexToDecimal(tmp2);
    strncpy(tmp2,tmp+6,2);
    macaddr[2] = convertHexToDecimal(tmp2);
    strncpy(tmp2,tmp+9,2);
    macaddr[3] = convertHexToDecimal(tmp2);
    strncpy(tmp2,tmp+12,2);
    macaddr[4] = convertHexToDecimal(tmp2);
    strncpy(tmp2,tmp+15,2);
    macaddr[5] = convertHexToDecimal(tmp2);
    printf("mac: %.2X:%.2X:%.2X:%.2X:%.2X:%.2X\n",macaddr[0],macaddr[1],macaddr[2],macaddr[3],macaddr[4],macaddr[5]);
    f_close(&fil);
#endif
#ifdef  MAC_IN_DECIMAL
    char tmp[33];
    char tmp2[3];
    f_open(&fil, "mac10", FA_OPEN_ALWAYS | FA_READ );
    f_lseek(&fil, 0);
    f_gets(tmp, 24, &fil);
    strncpy(tmp2,tmp,3);
    macaddr[0] = atoi(tmp2);
    strncpy(tmp2,tmp+4,3);
    macaddr[1] = atoi(tmp2);
    strncpy(tmp2,tmp+8,3);
    macaddr[2] = atoi(tmp2);
    strncpy(tmp2,tmp+12,3);
    macaddr[3] = atoi(tmp2);
    strncpy(tmp2,tmp+16,3);
    macaddr[4] = atoi(tmp2);
    strncpy(tmp2,tmp+20,3);
    macaddr[5] = atoi(tmp2);
    printf("mac: %.2X:%.2X:%.2X:%.2X:%.2X:%.2X\n",macaddr[0],macaddr[1],macaddr[2],macaddr[3],macaddr[4],macaddr[5]);
    f_close(&fil);
#endif
}

void setParametersFromSD()
{
    Printf("\nSet IP Parameters from SD\r\n");
    char tmp[33];
    char tmp2[3];
    f_open(&fil, "host_IP", FA_OPEN_ALWAYS | FA_READ );
    f_gets(tmp, 16, &fil);
    strcpy(host_IP, tmp);
    strncpy(tmp2,tmp,3);
    ipaddr[0] = atoi(tmp2);
    strncpy(tmp2,tmp+4,3);
    ipaddr[1] = atoi(tmp2);
    strncpy(tmp2,tmp+8,3);
    ipaddr[2] = atoi(tmp2);
    strncpy(tmp2,tmp+12,3);
    ipaddr[3] = atoi(tmp2);
    printf("host_IP: %d.%d.%d.%d\r\n",ipaddr[0],ipaddr[1],ipaddr[2],ipaddr[3]);
    f_close(&fil);

    f_open(&fil, "dest_IP", FA_OPEN_ALWAYS | FA_READ );
    f_gets(tmp, 16, &fil);
    strcpy(dest_IP, tmp);
    strncpy(tmp2,tmp,3);
    destip[0] = atoi(tmp2);
    strncpy(tmp2,tmp+4,3);
    destip[1] = atoi(tmp2);
    strncpy(tmp2,tmp+8,3);
    destip[2] = atoi(tmp2);
    strncpy(tmp2,tmp+12,3);
    destip[3] = atoi(tmp2);
    printf("dest_IP: %d.%d.%d.%d\r\n",destip[0],destip[1],destip[2],destip[3]);
    f_close(&fil);

    f_open(&fil, "gate_IP", FA_OPEN_ALWAYS | FA_READ );
    f_gets(tmp, 16, &fil);
    strcpy(gate_IP, tmp);
    strncpy(tmp2,tmp,3);
    ipgate[0] = atoi(tmp2);
    strncpy(tmp2,tmp+4,3);
    ipgate[1] = atoi(tmp2);
    strncpy(tmp2,tmp+8,3);
    ipgate[2] = atoi(tmp2);
    strncpy(tmp2,tmp+12,3);
    ipgate[3] = atoi(tmp2);
    printf("gate_IP: %d.%d.%d.%d\r\n",ipgate[0],ipgate[1],ipgate[2],ipgate[3]);
    f_close(&fil);

    f_open(&fil, "mask_IP", FA_OPEN_ALWAYS | FA_READ );
    f_gets(tmp, 16, &fil);
    strcpy(mask_IP, tmp);
    strncpy(tmp2,tmp,3);
    ipmask[0] = atoi(tmp2);
    strncpy(tmp2,tmp+4,3);
    ipmask[1] = atoi(tmp2);
    strncpy(tmp2,tmp+8,3);
    ipmask[2] = atoi(tmp2);
    strncpy(tmp2,tmp+12,3);
    ipmask[3] = atoi(tmp2);
    printf("mask_IP: %d.%d.%d.%d\r\n",ipmask[0],ipmask[1],ipmask[2],ipmask[3]);
    f_close(&fil);

    f_open(&fil, "md5", FA_OPEN_ALWAYS | FA_READ );
    f_gets(tmp, 33, &fil);
    strncpy(MD5, tmp, 32);
    f_close(&fil);
    MD5[32] = '\0';
    printf("md5: %s\r\n",MD5);
}

void SetParaametersFromEEPROM()
{
#ifdef LFS
    char tmp[100];
    char tmp5[23];
    char tmp6[3];
    printf_DMA("Load data from EEPROM\r\n"); delayUS_ASM(10000);
    lfs_file_open(&lfs, &file, "host_IP", LFS_O_RDWR | LFS_O_CREAT);
    lfs_file_read(&lfs, &file, &tmp5, sizeof (tmp5));
    lfs_file_close(&lfs, &file);
    strncpy(tmp6,tmp5,3);
    ipaddr[0] = atoi(tmp6);
    strncpy(tmp6,tmp5+5,3);
    ipaddr[1] = atoi(tmp6);
    strncpy(tmp6,tmp5+10,3);
    ipaddr[2] = atoi(tmp6);
    strncpy(tmp6,tmp5+15,3);
    ipaddr[3] = atoi(tmp6);

    lfs_file_open(&lfs, &file, "dest_IP", LFS_O_RDWR | LFS_O_CREAT);
    lfs_file_read(&lfs, &file, &tmp5, sizeof (tmp5));
    lfs_file_close(&lfs, &file);
    strncpy(tmp6,tmp5,3);
    destip[0] = atoi(tmp6);
    strncpy(tmp6,tmp5+5,3);
    destip[1] = atoi(tmp6);
    strncpy(tmp6,tmp5+10,3);
    destip[2] = atoi(tmp6);
    strncpy(tmp6,tmp5+15,3);
    destip[3] = atoi(tmp6);

    lfs_file_open(&lfs, &file, "gate_IP", LFS_O_RDWR | LFS_O_CREAT);
    lfs_file_read(&lfs, &file, &tmp5, sizeof (tmp5));
    lfs_file_close(&lfs, &file);
    strncpy(tmp6,tmp5,3);
    ipgate[0] = atoi(tmp6);
    strncpy(tmp6,tmp5+5,3);
    ipgate[1] = atoi(tmp6);
    strncpy(tmp6,tmp5+10,3);
    ipgate[2] = atoi(tmp6);
    strncpy(tmp6,tmp5+15,3);
    ipgate[3] = atoi(tmp6);

    lfs_file_open(&lfs, &file, "mask_IP", LFS_O_RDWR | LFS_O_CREAT);
    lfs_file_read(&lfs, &file, &tmp5, sizeof (tmp5));
    lfs_file_close(&lfs, &file);
    strncpy(tmp6,tmp5,3);
    ipmask[0] = atoi(tmp6);
    strncpy(tmp6,tmp5+5,3);
    ipmask[1] = atoi(tmp6);
    strncpy(tmp6,tmp5+10,3);
    ipmask[2] = atoi(tmp6);
    strncpy(tmp6,tmp5+15,3);
    ipmask[3] = atoi(tmp6);

    lfs_file_open(&lfs, &file, "md5", LFS_O_RDWR | LFS_O_CREAT);
    lfs_file_read(&lfs, &file, &tmp, sizeof (tmp));
    lfs_file_close(&lfs, &file);
    strcpy(MD5, tmp);

    sprintf(tmp,"host_IP: %d.%d.%d.%d\r\n",ipaddr[0],ipaddr[1],ipaddr[2],ipaddr[3]);
    Printf(tmp);
    sprintf(tmp,"dest_IP: %d.%d.%d.%d\r\n",destip[0],destip[1],destip[2],destip[3]);
    Printf(tmp);
    sprintf(tmp,"gate_IP: %d.%d.%d.%d\r\n",ipgate[0],ipgate[1],ipgate[2],ipgate[3]);
    Printf(tmp);
    sprintf(tmp,"mask_IP: %d.%d.%d.%d\r\n",ipmask[0],ipmask[1],ipmask[2],ipmask[3]);
    Printf(tmp);
    sprintf(tmp,"md5: %s", MD5);
    Printf(tmp);

    sprintf(tmp,"mac: %.2X:%.2X:%.2X:%.2X:%.2X:%.2X\r\n",macaddr[0],macaddr[1],macaddr[2],macaddr[3],macaddr[4],macaddr[5]);
    Printf(tmp);
#endif
}

void wep_define_func(void)
{
#ifdef   NEW_HTTP_SERVER
    // Index page and netinfo / base64 image demo
#ifdef   PROD
    reg_httpServer_webContent((uint8_t *)"index.html", (uint8_t *)index_page);				// index.html 		: Main page example
    reg_httpServer_webContent((uint8_t *)"main.html", (uint8_t *)main_page);                // main.html
    reg_httpServer_webContent((uint8_t *)"fake.html", (uint8_t *)fake_page);                // fake.html
    reg_httpServer_webContent((uint8_t *)"host_IP", (uint8_t *)host_IP);
    reg_httpServer_webContent((uint8_t *)"dest_IP", (uint8_t *)dest_IP);
    reg_httpServer_webContent((uint8_t *)"gate_IP", (uint8_t *)gate_IP);
    reg_httpServer_webContent((uint8_t *)"mask_IP", (uint8_t *)mask_IP);
    reg_httpServer_webContent((uint8_t *)"mac_adr", (uint8_t *)mac);
    reg_httpServer_webContent((uint8_t *)"version", (uint8_t *)version);
    reg_httpServer_webContent((uint8_t *)"mode", (uint8_t *)mode);
#endif
#ifndef   PROD
    reg_httpServer_webContent((uint8_t *)"index.html", (uint8_t *)index_page_WIZNET);       //web сервер WIZNET
    reg_httpServer_webContent((uint8_t *)"netinfo.html", (uint8_t *)netinfo_page);			// netinfo.html 	: Network information example page
    reg_httpServer_webContent((uint8_t *)"img.html", (uint8_t *)img_page);					// img.html 		: Base64 Image data example page
    reg_httpServer_webContent((uint8_t *)"dio.html", (uint8_t *)dio_page);					// dio.html 		: Digital I/O control example page
// js файлы внесены в код html
//    reg_httpServer_webContent((uint8_t *)"netinfo.js", (uint8_t *)w5x00web_netinfo_js);     // netinfo.js 		: JavaScript for Read Network configuration 	(+ ajax.js)
//    reg_httpServer_webContent((uint8_t *)"dio.js", (uint8_t *)w5x00web_dio_js);             // dio.js 			: JavaScript for digital I/O control 	(+ ajax.js)
//    reg_httpServer_webContent((uint8_t *)"ajax.js", (uint8_t *)w5x00web_ajax_js);			// ajax.js			: JavaScript for AJAX request transfer
#endif
#endif //NEW_HTTP_SERVER
}

void net_ini_WIZNET(uint8_t socketTCP)
{
//    printf("net_ini_WIZNET_WEB\r\n");

    HAL_GPIO_WritePin(GPIOC, GPIO_PIN_9, GPIO_PIN_RESET);
    HAL_Delay(70);
    HAL_GPIO_WritePin(GPIOC, GPIO_PIN_9, GPIO_PIN_SET);
    HAL_Delay(70);
    uint8_t sn_TCP = socketTCP;
    WIZCHIPInitialize();

//    printf("WIZCHIPInitialize  OK\r\n");

    for (int i =0; i < 6; ++i)
    {
        defaultNetInfo.mac[i] = macaddr[i];
    }
    for (int i =0; i < 4; ++i)
    {
        defaultNetInfo.ip[i] = ipaddr[i];
        defaultNetInfo.gw[i] = ipgate[i];
        defaultNetInfo.sn[i] = ipmask[i];
    }

    ctlnetwork(CN_SET_NETINFO, (void*) &defaultNetInfo);
//    print_network_information();
    socket(sn_TCP, Sn_MR_TCP, local_port_web, 0/*SF_UNI_BLOCK*/); //У W5500 4 флага
    if (SOCK_OK == listen(sn_TCP))
        printf("socket %d (WEB) listening\r\n", sn_TCP);
}

FRESULT checkFileOnSD(FIL* fp, const TCHAR* path){
    f_open(fp, path, FA_READ );
    uint32_t numByte = fp->obj.objsize;
    f_close(fp);
    if (numByte > 0) {
        return FR_OK;
    }
    else {
        return FR_NO_FILE;
    }
}

void isSdCartOn()
{
    if (
        (checkFileOnSD(&fil,"host_IP") == FR_OK) &&
        (checkFileOnSD(&fil,"dest_IP") == FR_OK) &&
        (checkFileOnSD(&fil,"mask_IP") == FR_OK) &&
        (checkFileOnSD(&fil,"gate_IP") == FR_OK) &&
        (checkFileOnSD(&fil,"md5") == FR_OK)
        )
    {
        printf("\r\n*********** found IP settings on SD ************\r\n");
    }
    else
    {
        sdCartOn = 0;
        HAL_GPIO_WritePin(GPIOD, GPIO_PIN_2, GPIO_PIN_SET);     //EEPROM SPI
        HAL_GPIO_WritePin(GPIOE, GPIO_PIN_2, GPIO_PIN_RESET);   //SD
        printf("******** IP setting loading from eeprom ********\r\n");
    }
    f_close(&fil);
}

void workI2C_EEPROM()
{//Забираем только MAC !!!
//      simpleTestI2C_EEPROM(simpleTestEEPROMadress);

//Дальше работаю без  littleFsInit  глюки при записи больших файлов !!!
//      littleFsInit();
//      Printf("FsEeprom TEST ... ");
//      FsForEeprom_test();

//        markEEPROMasNew(); //Ручная установка EEPROM как NEW
//    if (sdCartOn == 0)
//    {
//        if (eepromCLEAR == isEEPROMclear(markEEPROMclear)) //Проверяем EEPROM новая ли
//        {
//            printf("EEPROM: NEW\n");
//            // Пишем на eeprom все параметры по умолчанию
//            copyDefaultParametersToAdressEEPROM(ipSettingAdressInEEPROM);
//            copyDefaultMACToAdressEEPROM(macAdressInEEPROM);
//            SetMacFromAdressEEPROM(macAdressInEEPROM);
//            markEEPROMasOld(); // Снимаем признак новая EEPROM
//        }
//        else
//        {
//            printf("EEPROM: OLD\r\n");
//        }

//    }

    if (sdCartOn == 1)
    {
//        setParametersFromSD();
//        copyParametersFromSDToAdressEEPROM(ipSettingAdressInEEPROM);
        copyMacToAdressEEPROM(macAdressInEEPROM);
        setMacFromSD();
#ifndef   NEW_HTTP_SERVER
        copyFileToAdressEEPROM("index.html", indexAdressInEEPROM);
        copyFileToAdressEEPROM("main.html", mainAdressInEEPROM);
#endif
#ifdef LFS
//lfs не использую
//        copyParametersToEEPROM();
//        copyFileToEEPROM("index.html");
//        copyFileToEEPROM("main.html");
#endif
    } else //Установка параметров с i2c eeprom
    {
//        SetParaametersFromAdressEEPROM(ipSettingAdressInEEPROM);
        SetMacFromAdressEEPROM(macAdressInEEPROM);
#ifndef   NEW_HTTP_SERVER
        //Загружаем длины файлов
        char tmp[5];
        uint16_t numByteLen = 5;
        uint16_t * len = &numByteLen;
        BSP_EEPROM_ReadBuffer((uint8_t*)tmp, indexLenAdressInEEPROM, len);
        indexLen = atoi(tmp);
        printf("index.html len - %d\n", indexLen);
        BSP_EEPROM_ReadBuffer((uint8_t*)tmp, mainLenAdressInEEPROM, len);
        mainLen = atoi(tmp);
        printf("main.html len - %d\n", mainLen);

        loadFilesFromEepromToMemory(indexAdressInEEPROM, indexLen,
                                    mainAdressInEEPROM, mainLen,
                                    ipSettingAdressInEEPROM, settingsLen);
//        printFilesFromMemory();
//        printFileFromAdressEEPROM(indexAdressInEEPROM, indexLen); //index.html
//        printFileFromAdressEEPROM(mainAdressInEEPROM, mainLen); //main.html
#endif
#ifdef LFS
//lfs не использую
//        SetParaametersFromEEPROM();
//        testReadFile("index.html");
//        testReadFile("main.html");
//        printFileFromEEPROM("index.html");
//        printFileFromEEPROM("main.html");
#endif
    }
}

void initSPI_EEPROM()
{
    HAL_GPIO_WritePin(GPIOD, GPIO_PIN_2, GPIO_PIN_SET);
    EEPROM_SPI_INIT(&hspi3);
//    printEepromSpiStatus();
}

void workSPI_EEPROM()
{
    if (setResetTwice == 0)
    {
    //    testSPI_EEPROM();

    //    markSPIEEPROMasNew(markEEPROMSPIclear); //Ручная установка SPIEEPROM как NEW
        if (sdCartOn == 0)
        {
            if (eepromSPICLEAR == isSPIEEPROMclear(markEEPROMSPIclear)) //Проверяем EEPROM новая ли
            {
                printf("SPI EEPROM: NEW\n");
            // Пишем на eeprom все параметры по умолчанию
                copyDefaultParametersToAdressSPIEEPROM(ipSettingAdressInSPIEEPROM);
//                copyDefaultMACToAdressSPIEEPROM(macAdressInSPIEEPROM);
                markSPIEEPROMasOld(markEEPROMSPIclear); // Снимаем признак новая EEPROM
            }
            else
            {
//                printf("SPI EEPROM: OLD\r\n");
            }
        }

        if (sdCartOn == 1)
        {
            setParametersFromSD();
            copyParametersFromSDToAdressSPIEEPROM(ipSettingAdressInSPIEEPROM); //Копируем Settings из SD в SPI eeprom
//            copyMacToAdressSPIEEPROM(macAdressInSPIEEPROM);                    //Копируем MAC из SD в SPI eeprom
//            setMacFromSD();
        } else //Установка параметров с SPI eeprom
        {
            SetParaametersFromAdressSPIEEPROM(ipSettingAdressInEEPROM);
//            SetMacFromAdressSPIEEPROM(macAdressInEEPROM);
        }
    } else {//Дважды нажат сброс - восстановление дефолтных значений
        copyDefaultParametersToAdressSPIEEPROM(ipSettingAdressInSPIEEPROM);
//        copyDefaultMACToAdressSPIEEPROM(macAdressInSPIEEPROM);
        SetParaametersFromAdressSPIEEPROM(ipSettingAdressInEEPROM);
        green_blink
        green_blink
        green_blink
        HAL_NVIC_SystemReset();
//        SetMacFromAdressSPIEEPROM(macAdressInEEPROM);
    }
}
#if 0
GPIO для дебага
HAL_GPIO_WritePin(GPIOD, GPIO_PIN_0, GPIO_PIN_SET); //81 pin
HAL_GPIO_WritePin(GPIOD, GPIO_PIN_1, GPIO_PIN_SET); //82 pin
HAL_GPIO_WritePin(GPIOD, DEBUG1_Pin, GPIO_PIN_SET); //84 pin  1 pin Debug  send
HAL_GPIO_WritePin(GPIOD, DEBUG2_Pin, GPIO_PIN_SET); //85 pin  2 pin Debug  receive
HAL_GPIO_WritePin(GPIOD, DEBUG3_Pin, GPIO_PIN_SET); //86 pin  3 pin Debug  Обмен с ПЛИС
HAL_GPIO_WritePin(GPIOD, GPIO_PIN_6, GPIO_PIN_SET); //87 pin
HAL_GPIO_WritePin(GPIOD, GPIO_PIN_7, GPIO_PIN_SET); //88 pin
HAL_GPIO_WritePin(GPIOD, GPIO_PIN_9, GPIO_PIN_SET); //56 pin
HAL_GPIO_WritePin(GPIOD, GPIO_PIN_10, GPIO_PIN_SET); //57 pin
HAL_GPIO_WritePin(GPIOD, GPIO_PIN_13, GPIO_PIN_SET); //60 pin
HAL_GPIO_WritePin(GPIOD, GPIO_PIN_15, GPIO_PIN_SET); //Синий
HAL_GPIO_WritePin(GPIOD, GPIO_PIN_12, GPIO_PIN_SET); //Зеленый
HAL_GPIO_WritePin(GPIOD, GPIO_PIN_14, GPIO_PIN_SET); //Красный

PE15  - cs Wifi
#endif

void prepearUDP_PLIS(uint8_t udpSocket)
{
    socket(udpSocket, Sn_MR_UDP, local_port_udp , 0x00);
}

void convertToBaseData(){ //в С канале инвертируем все кроме 2 бита
    for (uint16_t i = 1; i <= MAX_PACKET_LEN - 3; i = i + 4) {
//        dataFromDx[i] = ~dataFromDx[i];
//        dataFromDx[i] ^= 0x04;
        dataFromDx[i] ^= 0xFB;
    }
}

void convertToAbonData(){ //в С канале инвертируем все кроме 2 бита
    for (uint16_t i = 1; i <= MAX_PACKET_LEN - 3; i = i + 4) {
//        dataFromBase[i] = ~dataFromBase[i];
//        dataFromBase[i] ^= 0x04;
        dataFromBase[i] ^= 0xFB;
    }
}

void sendReceiveUDP(uint8_t udpSocket)
{
    if ((ABONENT_or_BASE == BASE) && (NET_DIAGNOSTIC_BASE == 0) && (HAL_GetTick() < 5000)) {//Только 5 секунд проверяем
        if (netDiagnosticON == checkNetDiagnosticMode()){
            printf("netDiagnosticON\r\n");
            NET_DIAGNOSTIC_BASE = 1;

            //Сбрасываю флаг диагностики
            uint8_t netDiagnostic[1];
            netDiagnostic[0] = 0xFF;
            EEPROM_SPI_WriteBuffer(netDiagnostic, netDiagnosticFlag, 1);
            printf("netDiagnosticFlag set OFF\r\n");
        }
    }
    if ((ABONENT_or_BASE == ABONENT) && (NET_DIAGNOSTIC_ABON == 0) && (HAL_GetTick() < 5000)) {//Только 5 секунд проверяем
        if (netDiagnosticON == checkNetDiagnosticMode()){
            printf("netDiagnosticON\r\n");
            NET_DIAGNOSTIC_ABON = 1;

            //Сбрасываю флаг диагностики
            uint8_t netDiagnostic[1];
            netDiagnostic[0] = 0xFF;
            EEPROM_SPI_WriteBuffer(netDiagnostic, netDiagnosticFlag, 1);
            printf("netDiagnosticFlag set OFF\r\n");
        }
    }

// CPU_INT Жду пока плис поднимет флаг
    if(HAL_GPIO_ReadPin(GPIOB, GPIO_PIN_15) == GPIO_PIN_SET)
    {
        HAL_GPIO_WritePin(GPIOD, DEBUG3_Pin, GPIO_PIN_SET);
        if (ABONENT_or_BASE == BASE) {
#ifdef  enable_RESET_FPGA_MOSI
//Очищаю сдвиговый регистр передачи MOSI
            HAL_GPIO_WritePin(GPIOC, GPIO_PIN_5, GPIO_PIN_SET);
            HAL_GPIO_WritePin(GPIOC, GPIO_PIN_5, GPIO_PIN_RESET);
#endif
            //Обмен с ПЛИС
            //Данные от ПЛИС кладу в буфер

            HAL_SPI_TransmitReceive(&hspi2,
                                    #ifndef  fpgaToCpuBaseTestData
                                    dataToBase ,
                                    #endif
                                    #ifdef  fpgaToCpuBaseTestData
                                    test1 ,
                                    #endif
                                    #ifndef  cpuToFpgaBaseTestData
                                    dataFromBase ,
                                    #endif
                                    #ifdef  cpuToFpgaBaseTestData
                                    test1 ,
                                    #endif
                                    MAX_PACKET_LEN, 0x10000);
#ifdef  enable_RESET_FPGA_MISO
            //Очищаю сдвиговый регистр приема MISO
            HAL_GPIO_WritePin(GPIOA, GPIO_PIN_8, GPIO_PIN_SET);
            HAL_GPIO_WritePin(GPIOA, GPIO_PIN_8, GPIO_PIN_RESET);
#endif

#ifdef enable_BUFFER_FIFO
//Копирую данные для отправки абоненту в буфер
            strncpy(bufDataFromBase + MAX_PACKET_LEN * indexFpgaBufData,
                    (char *) dataFromBase, MAX_PACKET_LEN );
            ++indexFpgaBufData;
            if (indexFpgaBufData == BUF_PACKET_SIZE)
                indexFpgaBufData = 0;
#endif

//Поиск телеграммы

//Тут вывожу все каналы, полученные от базы  dataFromBase
//Формируем массив из байтов 3 канала
#ifdef enable_CONTROL
            create_2_channelDataForControl(dataFromBase, receivedDataFrom_2_Channel);
#endif
            if (SEGGER){
                print_Channel(1, dataFromBase);
                print_Channel(2, dataFromBase);
                print_Channel(3, dataFromBase);
                print_Channel(4, dataFromBase);
//                print_Channel(1, dataToBase);
//                print_Channel(2, dataToBase);
//                print_Channel(3, dataToBase);
//                print_Channel(4, dataToBase);

//                print_ALL_Channel(dataFromBase);
            }
#ifdef enable_CONTROL
//Логика перезагрузки - проверяю 2-й канал если не EE в течение 40 сек то перезагрузка
            if (compare_data_in_Channel(receivedDataFrom_2_Channel, trueDataFrom_2_Channel) != 0){
                ++compareDataInChannelState;
                if (compareDataInChannelState == ERROR_1){
                    numGoodPackets2Channel = 0;
                    bridgeState = CONNECTION_NO;
                    uint32_t currTime = HAL_GetTick();
                    printf_DMA("*** Connection LOST ******* System time %dd %dh %dm %ds \r\n",
                                currTime/(24 * 3600000),
                                (currTime/3600000) % 24,
                                (currTime/60000) % 60,
                                (currTime/1000) % 60);
                }
                ++numBadPackets2Channel; //Инкрементируем счетчик
                numGoodPackets2Channel = 0;
                if (SEGGER){
                    SEGGER_RTT_SetTerminal(6);
                    SEGGER_RTT_printf(0, "bad packets: %d\r\n", numBadPackets2Channel);
                    SEGGER_RTT_SetTerminal(0);
                }
            }
            else {
                ++numGoodPackets2Channel;
                if (numGoodPackets2Channel == 100){ //Подряд 100 хороших пакетов
                    numBadPackets2Channel = 0;
                    compareDataInChannelState = NO_ERRORS;
                    bridgeState = CONNECTION_YES;
                    uint32_t currTime = HAL_GetTick();
                    printf_DMA("*** Connection state OK *** System time %dd %dh %dm %ds \r\n",
                               currTime/(24 * 3600000),
                               (currTime/3600000) % 24,
                               (currTime/60000) % 60,
                               (currTime/1000) % 60);
                    bridgeState = CONNECTION_YES;
                }//100
            }//совпало

            if (numBadPackets2Channel == 80000/MAX_PACKET_LEN) {//За 10 секунды связь не встала (8000/MAX_PACKET_LEN * 10)
// Команда абоненту на перезагрузку
                sendto(udpSocket, (uint8_t *)commandfromBaseToAbonentReboot, MAX_PACKET_LEN, destip, local_port_udp);
                printf("Sending command Reboot to abonent\r\n");
                red_blink  red_blink  red_blink
                reboot();
            }
#endif
            if ((NET_DIAGNOSTIC_BASE == 1) && (NET_DIAGNOSTIC_ABON == 0) ){
// Команда абоненту - перейти в диагностический режим
                sendto(UDP_SOCKET, (uint8_t *)commandfromBaseToAbonentNetDiagnostic, MAX_PACKET_LEN, destip, local_port_udp);
                printf("Send commant to abonent: net diagnostic mode\r\n");
                red_blink  red_blink  red_blink
                NET_DIAGNOSTIC_ABON = 1;
                HAL_Delay(1000);
//Тут дальше диагностика от базы
                netDiagnosticBase();

            }
            HAL_GPIO_WritePin(GPIOD, DEBUG3_Pin, GPIO_PIN_RESET);

            sendPackets(udpSocket, destip, local_port_udp);
            receivePackets(udpSocket, destip, local_port_udp);

        }

        if (ABONENT_or_BASE == ABONENT) {
#ifdef  enable_RESET_FPGA_MOSI
//Очищаю сдвиговый регистр передачи MOSI
            HAL_GPIO_WritePin(GPIOC, GPIO_PIN_5, GPIO_PIN_SET);
            HAL_GPIO_WritePin(GPIOC, GPIO_PIN_5, GPIO_PIN_RESET);
#endif
            //Обмен с ПЛИС
            HAL_SPI_TransmitReceive(&hspi2,
                                    #ifndef  fpgaToCpuAbonTestData
                                    dataToDx ,
                                    #endif
                                    #ifdef  fpgaToCpuAbonTestData
                                    test1 ,
                                    #endif
                                    #ifndef  cpuToFpgaAbonTestData
                                    dataFromDx ,
                                    #endif
                                    #ifdef  cpuToFpgaAbonTestData
                                    test1 ,
                                    #endif
                                    MAX_PACKET_LEN, 0x10000);
#ifdef  enable_RESET_FPGA_MISO
            //Очищаю сдвиговый регистр приема MISO
            HAL_GPIO_WritePin(GPIOA, GPIO_PIN_8, GPIO_PIN_SET);
            HAL_GPIO_WritePin(GPIOA, GPIO_PIN_8, GPIO_PIN_RESET);
#endif

#ifdef enable_BUFFER_FIFO
//Копирую данные для отправки базе в буфер
            strncpy(bufDataFromAbon + MAX_PACKET_LEN * indexFpgaBufData,
                    (char *) dataFromDx, MAX_PACKET_LEN );
            ++indexFpgaBufData;
            if (indexFpgaBufData == BUF_PACKET_SIZE)
                indexFpgaBufData = 0;
#endif

        HAL_GPIO_WritePin(GPIOD, DEBUG3_Pin, GPIO_PIN_RESET);//Дебаг обмен с ПЛИС завершен

        //Тут вывожу все каналы, полученные от абонента  dataFromDx
        if (SEGGER){
            print_Channel(1, dataFromDx);
            print_Channel(2, dataFromDx);
            print_Channel(3, dataFromDx);
            print_Channel(4, dataFromDx);
//            print_Channel(1, dataToDx);
//            print_Channel(2, dataToDx);
//            print_Channel(3, dataToDx);
//            print_Channel(4, dataToDx);

//            print_ALL_Channel(dataFromDx);
        }

            if ((NET_DIAGNOSTIC_BASE == 0) && (NET_DIAGNOSTIC_ABON == 1) ){
                // После перезагрузки
                printf("After reboot start net diagnostic mode\r\n");
                netDiagnosticAbon();
            }

            receivePackets(udpSocket, destip, local_port_udp);
            sendPackets(udpSocket, destip, local_port_udp);
        }
    }//if
}

void sendHANDSHAKE(uint8_t udpSocket) {

    uint32_t currTime = HAL_GetTick();
    uint32_t delay = 500;
    sendto(udpSocket, (uint8_t *)test1, MAX_PACKET_LEN, destip, local_port_udp);
    if (HAL_GetTick() < currTime + delay){ //Пакет отправился быстро - destip в сети
        HAL_GPIO_WritePin(GPIOD, Red_Led_Pin, GPIO_PIN_RESET);
        HANDSHAKE = hanshakeON;
    }
    else {
        printf("Waiting for destination connection %d ...\r\n", numWait);
        HAL_GPIO_WritePin(GPIOD, Green_Led_Pin, GPIO_PIN_RESET);
        HAL_GPIO_WritePin(GPIOD, Blue_Led_Pin, GPIO_PIN_RESET);
        red_blink
        red_blink
        HAL_IWDG_Refresh(&hiwdg);
        --numWait;
        if (numWait < 0)
            HAL_NVIC_SystemReset();
    }
}

void testSpiEepromWriteRead()
{
    //25AA1024  page = 256 byte,  512 pages
    printf("\ntestSpiEepromClearWriteRead\r\n");
    uint8_t RxBuffer[256] = {0x00};
    uint8_t TxBuffer[256] = {0x00};
    uint8_t err = 0;
    for (uint32_t adr = 0; adr< 0x1F000; adr += 4096) // должно быть 31 итерация
    {
        sprintf(TxBuffer,"%d", HAL_GetTick());
        EEPROM_SPI_WritePage(TxBuffer, adr, (uint16_t)256);
        EEPROM_SPI_ReadBuffer(RxBuffer, adr, (uint16_t)256);
        if (strcmp(TxBuffer, RxBuffer) == 0)
            printf("test SPI for address %5X OK data: %s\r\n", adr, TxBuffer);
        else
        {
            printf("test SPI for address %5X ERROR data: %s\r\n", adr, TxBuffer);
            err = 1;
        }
        if (err == 1)
            break;

    }
    if (err == 0)
        printf("Test SPI OK\r\n");
}

void testSpiEepromWritePage(uint32_t adr)
{
    uint8_t RxBuffer[256] = {0x00};
    HAL_Delay(1000);
    Printf("\nTest EEPROM_SPI_WritePage\n");
    EEPROM_SPI_ReadBuffer(RxBuffer, adr, (uint16_t)256);
    Printf("eeprom before write: %s\n", RxBuffer);
    Printf("Data to write: %s\n", TxBuffer);
    EEPROM_SPI_WritePage(TxBuffer, adr, (uint16_t)256);
    HAL_Delay(2000);
//    EEPROM_PowerDown();
//    HAL_Delay(1000);
//    EEPROM_WakeUP();
//    HAL_Delay(1000);
    EEPROM_SPI_ReadBuffer(RxBuffer, adr, (uint16_t)256);
    Printf("eeprom after write: %s\n", RxBuffer);

}

void testSpiEepromReadPage(uint32_t adr)
{
    uint8_t RxBuffer[256] = {0x00};
    Printf("Test EEPROM_SPI_ReadPage\r\n");
    EEPROM_SPI_ReadBuffer(RxBuffer, adr, (uint16_t)256);
    Printf("adress 0x%X read: %.256s\r\n", adr, RxBuffer);
}

void testSpiEepromWriteByte(uint32_t adr)
{
    uint8_t RxBuffer[256] = {0x00};
    HAL_Delay(1000);
    Printf("RX Buffer before write byte: %s\n", RxBuffer);
    EEPROM_SPI_ReadBuffer(RxBuffer, adr, (uint16_t)128);
    uint8_t byte[1] = "I";
    EEPROM_SPI_WriteByte(byte, adr);
    HAL_Delay(100);
    EEPROM_SPI_ReadBuffer(RxBuffer, adr, (uint16_t)128);
    Printf("RX Buffer awter write byte: %s\n", RxBuffer);
}

void testSPI_EEPROM()
{
    printf("\n-- Tests_SPI_EEPROM --\r\n");

//    EEPROM_CHIP_ERASE();
//    EEPROM_PAGE_ERASE(0x00000100); //PAGE_ERASE не работает
//    testSpiEepromWriteRead();
}

void copyDataFromI2cEepromToSpiEeprom()
{
#if 0
    0000 - 00FF   256b   IP settings
    0100 - 010F   16b    длина index.html
    0110 - 011F   16b    длина main.html
    0120 - 019F   128b   mac
#endif
    printf("copyDataFromI2cEepromToSpiEeprom\n");
    uint16_t numByteSettings = settingsLen;
    uint16_t * pnumByteSettings = &numByteSettings;
    uint16_t numByteMac = 18;
    uint16_t * pnumByteMac = &numByteMac;
    uint8_t tmpSettings[settingsLen];
    uint8_t tmpMac[settingsLen];
    BSP_EEPROM_ReadBuffer((uint8_t *)tmpSettings, 0x0000, pnumByteSettings);
    BSP_EEPROM_ReadBuffer((uint8_t *)tmpMac, 0x0120, pnumByteMac);

    HAL_GPIO_WritePin(GPIOD, GPIO_PIN_2, GPIO_PIN_SET);
    EEPROM_SPI_INIT(&hspi3);

    EEPROM_SPI_WriteBuffer(tmpSettings, 0x0000, settingsLen);
    EEPROM_SPI_WriteBuffer(tmpMac, 0x0120, 18);
    uint8_t SettBuff[settingsLen];
    uint8_t MacBuff[18];
    EEPROM_SPI_ReadBuffer(SettBuff, 0x0000, settingsLen);
    EEPROM_SPI_ReadBuffer(MacBuff, 0x0120, 18);
    printf("Settings: %s\n", SettBuff);
    printf("Mac: %s\n", MacBuff);
}

void reboot()
{
    printf("*****  REBOOT  *****\r\n");
#ifdef   NEW_HTTP_SERVER
    http_disconnect(HTTP_SOCKET);
#endif
    HAL_NVIC_SystemReset();
}

void checkLogin(char* buf)
{
    char login1[10] = {'a','d','m','i','n','\0'};
    char login2[10] = {'u','s','e','r','\0'};
    char loginSpecial[10] = {'g','i','t','a','d','m','i','n','\0'};
    if ((strcmp(buf + 5 ,login1) == 0) ||
        (strcmp(buf + 5,login2) == 0) ||
        (strcmp(buf + 5,loginSpecial) == 0))
    {
        printf("Login OK\n");
        loginState = loginON;
        if (strcmp(buf + 5,loginSpecial) == 0){
            passwordState = PasswordIgnore;
        }
    }
    else
    {
        printf("Login not found!!!\n");
        web = webOFF;
    }
}

void checkPassword(char* buf)
{
    if (passwordState == PasswordIgnore) //Был получен специальный логин
        passwordState = PasswordON;

    if (strncmp(buf + 8, MD5 , 32) == 0)
    {
        Printf("password OK\r\n");
        passwordState = PasswordON;
    }
    else
    {
        Printf("invalid password\r\n");
        if (passwordState == PasswordOFF){
            web = webOFF;
        }
    }
}

void setNewHostIP(char * tmpbuf)
{
    printf("setNewHostIP: %s\n",tmpbuf);
    uint8_t temp[4];
    char host_IP_1[3];char host_IP_2[3];char host_IP_3[3];char host_IP_4[3];
    int i=0;
    uint8_t j = 0;
    char oktet[3];
    while (1) {if(tmpbuf[i] == (uint8_t)'.') break; oktet[j] = tmpbuf[i]; i++; j++; }
    //i указывает на '.'  j - колл скопированных символов
    if (j == 3) {host_IP_1[0] = oktet[0]; host_IP_1[1] = oktet[1]; host_IP_1[2] = oktet[2];}
    if (j == 2) {host_IP_1[0] = '0'; host_IP_1[1] = oktet[0]; host_IP_1[2] = oktet[1];}
    if (j == 1) {host_IP_1[0] = '0'; host_IP_1[1] = '0'; host_IP_1[2] = oktet[0];}
    temp[0] = atoi(host_IP_1);
    i++; j=0;
    while (1) {if(tmpbuf[i] == (uint8_t)'.') break; oktet[j] = tmpbuf[i]; i++; j++; }
    if (j == 3) {host_IP_2[0] = oktet[0]; host_IP_2[1] = oktet[1]; host_IP_2[2] = oktet[2];}
    if (j == 2) {host_IP_2[0] = '0'; host_IP_2[1] = oktet[0]; host_IP_2[2] = oktet[1];}
    if (j == 1) {host_IP_2[0] = '0'; host_IP_2[1] = '0'; host_IP_2[2] = oktet[0];}
    temp[1] = atoi(host_IP_2);
    i++; j=0;
    while (1) {if(tmpbuf[i] == (uint8_t)'.') break; oktet[j] = tmpbuf[i]; i++; j++; }
    if (j == 3) {host_IP_3[0] = oktet[0]; host_IP_3[1] = oktet[1]; host_IP_3[2] = oktet[2];}
    if (j == 2) {host_IP_3[0] = '0'; host_IP_3[1] = oktet[0]; host_IP_3[2] = oktet[1];}
    if (j == 1) {host_IP_3[0] = '0'; host_IP_3[1] = '0'; host_IP_3[2] = oktet[0];}
    temp[2] = atoi(host_IP_3);
    i++; j=0;
    while (1) {if(tmpbuf[i] == (uint8_t)'\0') break; oktet[j] = tmpbuf[i]; i++; j++; }
    if (j == 3) {host_IP_4[0] = oktet[0]; host_IP_4[1] = oktet[1]; host_IP_4[2] = oktet[2];}
    if (j == 2) {host_IP_4[0] = '0'; host_IP_4[1] = oktet[0]; host_IP_4[2] = oktet[1];}
    if (j == 1) {host_IP_4[0] = '0'; host_IP_4[1] = '0'; host_IP_4[2] = oktet[0];}
    temp[3] = atoi(host_IP_4);

    if ((temp[0] == ipaddr[0])&&(temp[1] == ipaddr[1])&&(temp[2] == ipaddr[2])&&(temp[3] == ipaddr[3]))
    {
         printf("*****  hostIP not changed  *****\r\n");
    }
    else
    {
        ipaddr[0] = temp[0];
        ipaddr[1] = temp[1];
        ipaddr[2] = temp[2];
        ipaddr[3] = temp[3];
        printf("new host IP: %d.%d.%d.%d\r\n",ipaddr[0],ipaddr[1],ipaddr[2],ipaddr[3]);
        if (sdCartOn == 1)
        {
            FRESULT result = f_open(&fil, "host_IP", FA_OPEN_ALWAYS | FA_WRITE );
            if (result == 0)
            {
                printf("*****  write new host IP to SD  *****\n");
                UINT bw;
                char lf[1] = {'\n'};
                char tmp[16];
                strncpy(tmp,host_IP_1,3);
                strncpy(tmp+3,".",1);
                strncpy(tmp+4,host_IP_2,3);
                strncpy(tmp+7,".",1);
                strncpy(tmp+8,host_IP_3,3);
                strncpy(tmp+11,".",1);
                strncpy(tmp+12,host_IP_4,3);
                strncpy(tmp+15,lf, 1);
                f_write(&fil, tmp, 16, &bw);
                f_close(&fil);
            }
        }
        else //EEPROM
        {
            printf("*****  write new host IP to eeprom  *****\n");
            EEPROM_SPI_WriteBuffer((uint8_t *)host_IP_1, ipSettingAdressInSPIEEPROM, 3);
            EEPROM_SPI_WriteBuffer((uint8_t *)host_IP_2, ipSettingAdressInSPIEEPROM + 4, 3);
            EEPROM_SPI_WriteBuffer((uint8_t *)host_IP_3, ipSettingAdressInSPIEEPROM + 8, 3);
            EEPROM_SPI_WriteBuffer((uint8_t *)host_IP_4, ipSettingAdressInSPIEEPROM + 12, 3);
//            BSP_EEPROM_WriteBuffer((uint8_t *)host_IP_1, ipSettingAdressInEEPROM, 3);
//            BSP_EEPROM_WriteBuffer((uint8_t *)host_IP_2, ipSettingAdressInEEPROM + 4, 3);
//            BSP_EEPROM_WriteBuffer((uint8_t *)host_IP_3, ipSettingAdressInEEPROM + 8, 3);
//            BSP_EEPROM_WriteBuffer((uint8_t *)host_IP_4, ipSettingAdressInEEPROM + 12, 3);
        }
    }
}

void setNewMaskIP(char * tmpbuf)
{
    uint8_t temp[4];
    char mask_IP_1[3];char mask_IP_2[3];char mask_IP_3[3];char mask_IP_4[3];
    int i=0;
    uint8_t j = 0;
    char oktet[3];
    while (1) {if(tmpbuf[i] == (uint8_t)'.') break; oktet[j] = tmpbuf[i]; i++; j++; }
    //i указывает на '.'  j - колл скопированных символов
    if (j == 3) {mask_IP_1[0] = oktet[0]; mask_IP_1[1] = oktet[1]; mask_IP_1[2] = oktet[2]; }
    if (j == 2) {mask_IP_1[0] = '0'; mask_IP_1[1] = oktet[0]; mask_IP_1[2] = oktet[1];}
    if (j == 1) {mask_IP_1[0] = '0'; mask_IP_1[1] = '0'; mask_IP_1[2] = oktet[0];}
    temp[0] = atoi(mask_IP_1);
    i++; j=0;
    while (1) {if(tmpbuf[i] == (uint8_t)'.') break; oktet[j] = tmpbuf[i]; i++; j++; }
    if (j == 3) {mask_IP_2[0] = oktet[0]; mask_IP_2[1] = oktet[1]; mask_IP_2[2] = oktet[2];}
    if (j == 2) {mask_IP_2[0] = '0'; mask_IP_2[1] = oktet[0]; mask_IP_2[2] = oktet[1];}
    if (j == 1) {mask_IP_2[0] = '0'; mask_IP_2[1] = '0'; mask_IP_2[2] = oktet[0]; }
    temp[1] = atoi(mask_IP_2);
    i++; j=0;
    while (1) {if(tmpbuf[i] == (uint8_t)'.') break; oktet[j] = tmpbuf[i]; i++; j++; }
    if (j == 3) {mask_IP_3[0] = oktet[0]; mask_IP_3[1] = oktet[1]; mask_IP_3[2] = oktet[2];}
    if (j == 2) {mask_IP_3[0] = '0'; mask_IP_3[1] = oktet[0]; mask_IP_3[2] = oktet[1];}
    if (j == 1) {mask_IP_3[0] = '0'; mask_IP_3[1] = '0'; mask_IP_3[2] = oktet[0];}
    temp[2] = atoi(mask_IP_3);
    i++; j=0;
    while (1) {if(tmpbuf[i] == (uint8_t)'\0') break; oktet[j] = tmpbuf[i]; i++; j++; }
    if (j == 3) {mask_IP_4[0] = oktet[0]; mask_IP_4[1] = oktet[1]; mask_IP_4[2] = oktet[2];}
    if (j == 2) {mask_IP_4[0] = '0'; mask_IP_4[1] = oktet[0]; mask_IP_4[2] = oktet[1];}
    if (j == 1) {mask_IP_4[0] = '0'; mask_IP_4[1] = '0'; mask_IP_4[2] = oktet[0];}
    temp[3] = atoi(mask_IP_4);

    if ((temp[0] == ipmask[0])&&(temp[1] == ipmask[1])&&(temp[2] == ipmask[2])&&(temp[3] == ipmask[3]))
    {
         printf("*****  maskIP not changed  *****\n");
    }
    else
    {
        ipmask[0] = temp[0];
        ipmask[1] = temp[1];
        ipmask[2] = temp[2];
        ipmask[3] = temp[3];

        printf("new mask IP: %d.%d.%d.%d\r\n",ipmask[0],ipmask[1],ipmask[2],ipmask[3]);
        if (sdCartOn == 1)
        {
            FRESULT result = f_open(&fil, "mask_IP", FA_OPEN_ALWAYS | FA_WRITE );
            if (result == 0)
            {
                printf("*****  write new mask IP to SD  *****\n");
                UINT bw;
                char lf[1] = {'\n'};
                char tmp[16];
                strncpy(tmp,mask_IP_1,3);
                strncpy(tmp+3,".",1);
                strncpy(tmp+4,mask_IP_2,3);
                strncpy(tmp+7,".",1);
                strncpy(tmp+8,mask_IP_3,3);
                strncpy(tmp+11,".",1);
                strncpy(tmp+12,mask_IP_4,3);
                strncpy(tmp+15,lf, 1);
                f_write(&fil, tmp, 16, &bw);
                f_close(&fil);
            }
        }
        else //EEPROM
        {
            printf("*****  write new mask IP to eeprom  *****\n");
            EEPROM_SPI_WriteBuffer((uint8_t *)mask_IP_1, ipSettingAdressInSPIEEPROM + 45, 3);
            EEPROM_SPI_WriteBuffer((uint8_t *)mask_IP_2, ipSettingAdressInSPIEEPROM + 49, 3);
            EEPROM_SPI_WriteBuffer((uint8_t *)mask_IP_3, ipSettingAdressInSPIEEPROM + 54, 3);
            EEPROM_SPI_WriteBuffer((uint8_t *)mask_IP_4, ipSettingAdressInSPIEEPROM + 58, 3);
//            BSP_EEPROM_WriteBuffer((uint8_t *)mask_IP_1, ipSettingAdressInEEPROM + 45, 3);
//            BSP_EEPROM_WriteBuffer((uint8_t *)mask_IP_2, ipSettingAdressInEEPROM + 49, 3);
//            BSP_EEPROM_WriteBuffer((uint8_t *)mask_IP_3, ipSettingAdressInEEPROM + 54, 3);
//            BSP_EEPROM_WriteBuffer((uint8_t *)mask_IP_4, ipSettingAdressInEEPROM + 58, 3);
        }
    }
}

void setNewGateIP(char * tmpbuf)
{
    uint8_t temp[4];
    char gate_IP_1[3];char gate_IP_2[3];char gate_IP_3[3];char gate_IP_4[3];
    int i=0;
    uint8_t j = 0;
    char oktet[3];
    while (1) {if(tmpbuf[i] == (uint8_t)'.') break; oktet[j] = tmpbuf[i]; i++; j++; }
    //i указывает на '.'  j - колл скопированных символов
    if (j == 3) {gate_IP_1[0] = oktet[0]; gate_IP_1[1] = oktet[1]; gate_IP_1[2] = oktet[2];}
    if (j == 2) {gate_IP_1[0] = '0'; gate_IP_1[1] = oktet[0]; gate_IP_1[2] = oktet[1];}
    if (j == 1) {gate_IP_1[0] = '0'; gate_IP_1[1] = '0'; gate_IP_1[2] = oktet[0];}
    temp[0] = atoi(gate_IP_1);
    i++; j=0;
    while (1) {if(tmpbuf[i] == (uint8_t)'.') break; oktet[j] = tmpbuf[i]; i++; j++; }
    if (j == 3) {gate_IP_2[0] = oktet[0]; gate_IP_2[1] = oktet[1]; gate_IP_2[2] = oktet[2];}
    if (j == 2) {gate_IP_2[0] = '0'; gate_IP_2[1] = oktet[0]; gate_IP_2[2] = oktet[1];}
    if (j == 1) {gate_IP_2[0] = '0'; gate_IP_2[1] = '0'; gate_IP_2[2] = oktet[0];}
    temp[1] = atoi(gate_IP_2);
    i++; j=0;
    while (1) {if(tmpbuf[i] == (uint8_t)'.') break; oktet[j] = tmpbuf[i]; i++; j++; }
    if (j == 3) {gate_IP_3[0] = oktet[0]; gate_IP_3[1] = oktet[1]; gate_IP_3[2] = oktet[2];}
    if (j == 2) {gate_IP_3[0] = '0'; gate_IP_3[1] = oktet[0]; gate_IP_3[2] = oktet[1];}
    if (j == 1) {gate_IP_3[0] = '0'; gate_IP_3[1] = '0'; gate_IP_3[2] = oktet[0];}
    temp[2] = atoi(gate_IP_3);
    i++; j=0;
    while (1) {if(tmpbuf[i] == (uint8_t)'\0') break; oktet[j] = tmpbuf[i]; i++; j++; }
    if (j == 3) {gate_IP_4[0] = oktet[0]; gate_IP_4[1] = oktet[1]; gate_IP_4[2] = oktet[2];}
    if (j == 2) {gate_IP_4[0] = '0'; gate_IP_4[1] = oktet[0]; gate_IP_4[2] = oktet[1];}
    if (j == 1) {gate_IP_4[0] = '0'; gate_IP_4[1] = '0'; gate_IP_4[2] = oktet[0];}
    temp[3] = atoi(gate_IP_4);

    if ((temp[0] == ipgate[0])&&(temp[1] == ipgate[1])&&(temp[2] == ipgate[2])&&(temp[3] == ipgate[3]))
    {
         Printf("*****  gateIP not changed  *****\r\n");
    }
    else
    {
        ipgate[0] = temp[0];
        ipgate[1] = temp[1];
        ipgate[2] = temp[2];
        ipgate[3] = temp[3];

        printf("new gate IP: %d.%d.%d.%d\r\n",ipgate[0],ipgate[1],ipgate[2],ipgate[3]);
        if (sdCartOn == 1)
        {
            FRESULT result = f_open(&fil, "gate_IP", FA_OPEN_ALWAYS | FA_WRITE );
            if (result == 0)
            {
                printf("*****  write new gate IP to SD  *****\n");
                UINT bw;
                char lf[1] = {'\n'};
                char tmp[16];
                strncpy(tmp,gate_IP_1,3);
                strncpy(tmp+3,".",1);
                strncpy(tmp+4,gate_IP_2,3);
                strncpy(tmp+7,".",1);
                strncpy(tmp+8,gate_IP_3,3);
                strncpy(tmp+11,".",1);
                strncpy(tmp+12,gate_IP_4,3);
                strncpy(tmp+15,lf, 1);
                f_write(&fil, tmp, 16, &bw);
                f_close(&fil);
            }
        }
        else //EEPROM
        {
            printf("*****  write new gate IP to eeprom  *****\n");
            EEPROM_SPI_WriteBuffer((uint8_t *)gate_IP_1, ipSettingAdressInSPIEEPROM + 30, 3);
            EEPROM_SPI_WriteBuffer((uint8_t *)gate_IP_2, ipSettingAdressInSPIEEPROM + 34, 3);
            EEPROM_SPI_WriteBuffer((uint8_t *)gate_IP_3, ipSettingAdressInSPIEEPROM + 38, 3);
            EEPROM_SPI_WriteBuffer((uint8_t *)gate_IP_4, ipSettingAdressInSPIEEPROM + 42, 3);
//            BSP_EEPROM_WriteBuffer((uint8_t *)gate_IP_1, ipSettingAdressInEEPROM + 30, 3);
//            BSP_EEPROM_WriteBuffer((uint8_t *)gate_IP_2, ipSettingAdressInEEPROM + 34, 3);
//            BSP_EEPROM_WriteBuffer((uint8_t *)gate_IP_3, ipSettingAdressInEEPROM + 38, 3);
//            BSP_EEPROM_WriteBuffer((uint8_t *)gate_IP_4, ipSettingAdressInEEPROM + 42, 3);
        }
    }
}

void setNewDestIP(char * tmpbuf)
{
    uint8_t temp[4];
    char dest_IP_1[3];char dest_IP_2[3];char dest_IP_3[3];char dest_IP_4[3];
    int i=0;
    uint8_t j = 0;
    char oktet[3];
    while (1) {if(tmpbuf[i] == (uint8_t)'.') break; oktet[j] = tmpbuf[i]; i++; j++; }
    //i указывает на '.'  j - колл скопированных символов
    if (j == 3) {dest_IP_1[0] = oktet[0]; dest_IP_1[1] = oktet[1]; dest_IP_1[2] = oktet[2];}
    if (j == 2) {dest_IP_1[0] = '0'; dest_IP_1[1] = oktet[0]; dest_IP_1[2] = oktet[1];}
    if (j == 1) {dest_IP_1[0] = '0'; dest_IP_1[1] = '0'; dest_IP_1[2] = oktet[0];}
    temp[0] = atoi(dest_IP_1);
    i++; j=0;
    while (1) {if(tmpbuf[i] == (uint8_t)'.') break; oktet[j] = tmpbuf[i]; i++; j++; }
    if (j == 3) {dest_IP_2[0] = oktet[0]; dest_IP_2[1] = oktet[1]; dest_IP_2[2] = oktet[2];}
    if (j == 2) {dest_IP_2[0] = '0'; dest_IP_2[1] = oktet[0]; dest_IP_2[2] = oktet[1];}
    if (j == 1) {dest_IP_2[0] = '0'; dest_IP_2[1] = '0'; dest_IP_2[2] = oktet[0];}
    temp[1] = atoi(dest_IP_2);
    i++; j=0;
    while (1) {if(tmpbuf[i] == (uint8_t)'.') break; oktet[j] = tmpbuf[i]; i++; j++; }
    if (j == 3) {dest_IP_3[0] = oktet[0]; dest_IP_3[1] = oktet[1]; dest_IP_3[2] = oktet[2];}
    if (j == 2) {dest_IP_3[0] = '0'; dest_IP_3[1] = oktet[0]; dest_IP_3[2] = oktet[1];}
    if (j == 1) {dest_IP_3[0] = '0'; dest_IP_3[1] = '0'; dest_IP_3[2] = oktet[0];}
    temp[2] = atoi(dest_IP_3);
    i++; j=0;
    while (1) {if(tmpbuf[i] == (uint8_t)'\0') break; oktet[j] = tmpbuf[i]; i++; j++; }
    if (j == 3) {dest_IP_4[0] = oktet[0]; dest_IP_4[1] = oktet[1]; dest_IP_4[2] = oktet[2];}
    if (j == 2) {dest_IP_4[0] = '0'; dest_IP_4[1] = oktet[0]; dest_IP_4[2] = oktet[1];}
    if (j == 1) {dest_IP_4[0] = '0'; dest_IP_4[1] = '0'; dest_IP_4[2] = oktet[0];}
    temp[3] = atoi(dest_IP_4);

    if ((temp[0] == destip[0])&&(temp[1] == destip[1])&&(temp[2] == destip[2])&&(temp[3] == destip[3]))
    {
         Printf("*****  destIP not changed  *****\r\n");
    }
    else
    {
        destip[0] = temp[0];
        destip[1] = temp[1];
        destip[2] = temp[2];
        destip[3] = temp[3];

        printf("new dest IP: %d.%d.%d.%d\r\n",destip[0],destip[1],destip[2],destip[3]);
        if (sdCartOn == 1)
        {
            FRESULT result = f_open(&fil, "dest_IP", FA_OPEN_ALWAYS | FA_WRITE );
            if (result == 0)
            {
                printf("*****  write new dest IP to SD  *****\n");
                UINT bw;
                char lf[1] = {'\n'};
                char tmp[16];
                strncpy(tmp,dest_IP_1,3);
                strncpy(tmp+3,".",1);
                strncpy(tmp+4,dest_IP_2,3);
                strncpy(tmp+7,".",1);
                strncpy(tmp+8,dest_IP_3,3);
                strncpy(tmp+11,".",1);
                strncpy(tmp+12,dest_IP_4,3);
                strncpy(tmp+15,lf, 1);
                f_write(&fil, tmp, 16, &bw);
                f_close(&fil);
            }
        }
        else //EEPROM
        {
            printf("*****  write new dest IP to eeprom  *****\n");
            EEPROM_SPI_WriteBuffer((uint8_t *)dest_IP_1, ipSettingAdressInSPIEEPROM + 15, 3);
            EEPROM_SPI_WriteBuffer((uint8_t *)dest_IP_2, ipSettingAdressInSPIEEPROM + 19, 3);
            EEPROM_SPI_WriteBuffer((uint8_t *)dest_IP_3, ipSettingAdressInSPIEEPROM + 23, 3);
            EEPROM_SPI_WriteBuffer((uint8_t *)dest_IP_4, ipSettingAdressInSPIEEPROM + 27, 3);
//            BSP_EEPROM_WriteBuffer((uint8_t *)dest_IP_1, ipSettingAdressInEEPROM + 15, 3);
//            BSP_EEPROM_WriteBuffer((uint8_t *)dest_IP_2, ipSettingAdressInEEPROM + 19, 3);
//            BSP_EEPROM_WriteBuffer((uint8_t *)dest_IP_3, ipSettingAdressInEEPROM + 23, 3);
//            BSP_EEPROM_WriteBuffer((uint8_t *)dest_IP_4, ipSettingAdressInEEPROM + 27, 3);
        }
    }
}

void setNewPassword(char * tmpbuf)
{
    printf("new pasword hash: %.32s",tmpbuf);
    printf("\r\n");
    if (sdCartOn == 1)
    {
        FRESULT result = f_open(&fil, "md5", FA_OPEN_ALWAYS | FA_WRITE );
        if (result == 0)
        {
            printf("*****  write new md5 to SD  *****\n");
            f_lseek(&fil, 0);
            f_puts(tmpbuf, &fil);
            f_sync(&fil);
            f_close(&fil);
        }
    }
    else //EEPROM
    {
        printf("*****  write new md5 to eeprom  *****\n");
        EEPROM_SPI_WriteBuffer((uint8_t *)tmpbuf, ipSettingAdressInSPIEEPROM + 60, 33);
//        BSP_EEPROM_WriteBuffer((uint8_t *)tmpbuf, ipSettingAdressInEEPROM + 60, 33);
    }
}

void checkTwinReset()
{
    // считываем значение по адресу resetTwiceFlag
    uint8_t twinReset[1];
    EEPROM_SPI_ReadBuffer(twinReset, resetTwiceFlag, 1);
    if (twinReset[0] == 0x88) {
        setResetTwice = 1; //Был нажат двойной сброс - восстановить значения по умолчанию
        printf("Set reset twice  - restore default srttings!!!\r\n");
    }
    else {
        twinReset[0] = 0x88;
        EEPROM_SPI_WriteBuffer(twinReset, resetTwiceFlag, 1);
    }
    if (setResetTwice == 0) {
        HAL_Delay(1000); //Ждем 1 секунду и пишем в SPI по адресу resetTwiceFlag отсутствие двойного нажатия - FF
    }

    twinReset[0] = 0xFF;
    EEPROM_SPI_WriteBuffer(twinReset, resetTwiceFlag, 1);
}

FLASH_OBProgramInitTypeDef	Fuses;
void ReadProtect(void) // защита от считывания
{

  HAL_FLASHEx_OBGetConfig(&Fuses);

  if (Fuses.RDPLevel != OB_RDP_LEVEL_1) {
    HAL_FLASH_Unlock(); // разрешаем запись
    HAL_FLASH_OB_Unlock(); // разрешаем запись

    Fuses.RDPLevel = OB_RDP_LEVEL_1;
    HAL_FLASHEx_OBProgram(&Fuses);

    HAL_FLASH_OB_Launch();
    HAL_FLASH_OB_Lock(); // запрещаем запись
    HAL_FLASH_Lock(); // запрещаем запись
  }
}

//extern uint8_t _sapp;
//extern uint8_t _eapp;
//extern uint8_t _smem;
/* USER CODE END 0 */

int main(void)
{

  /* MCU Configuration--------------------------------------------------------*/

  /* Reset of all peripherals, Initializes the Flash interface and the Systick. */
  HAL_Init();

  /* Configure the system clock */
  SystemClock_Config();

  /* Initialize all configured peripherals */
  MX_GPIO_Init();
  MX_DMA_Init();
  MX_USART6_UART_Init();
  MX_SPI3_Init();
  MX_SPI1_Init();
  MX_SPI2_Init();
  MX_FATFS_Init();
  MX_RNG_Init();
  MX_RTC_Init();
  MX_I2C1_Init();
  MX_USART2_UART_Init();
  MX_IWDG_Init();
  MX_CRC_Init();
  MX_I2C2_Init();
  /* USER CODE BEGIN 2 */
#ifdef  enable_SEGGER
  SEGGER = 1;
#endif
  red_blink //Индикация перезагрузки
  red_blink
  red_blink

//  printf("start address APP %d\r\n", (uint32_t*)&_sapp);
//  printf("end address APP %d\r\n", (uint32_t*)&_eapp);
//  printf("start address SHARED_MEMORY %d\r\n", (uint32_t*)&_smem);

// char version[6]  =  "02_02";

//    ReadProtect(); //   <---------------------- защита от считывания
    printf("************* Start main firmware **************\r\n");
    printf("version firmware: %.2d_%.2d\r\n", main_FW, patch_FW);
    sprintf(version, "%.2d_%.2d",main_FW, patch_FW);
    dataToNewSectionInFlash[0][0] = ' '; //Фиктивный вызов чтобы возникла секция
    printf("build: %.4d-%.2d-%.2d %.2X:%.2X:%.2X\r\n", 2000 + year_FW, month_FW, day_FW, hour_FW, minute_FW, second_FW);

    if (HAL_GPIO_ReadPin(GPIOC, GPIO_PIN_8) == GPIO_PIN_RESET){ //Я в централи - сигналл выдает ПЛИС
        ABONENT_or_BASE = BASE;
        printf("work in BASE\r\n");
        sprintf(mode, "Base   ");
        MX_IWDG_Init_base(); //Часть моста ближняя к базе перезагружается через 22 секунды
    }
    else { //Я в абоненте - сигналл выдает ПЛИС
        ABONENT_or_BASE = ABONENT;
        printf("work in ABONENT\r\n");
        sprintf(mode, "Abonent");
        MX_IWDG_Init_abonent(); //Часть моста ближняя к абоненту перезагружается через 26 секунд
    }
    f_mount(&fs, "", 0);
    isSdCartOn();       //Проверка вставлена ли SD карта
    workI2C_EEPROM();   //Только MAC
    initSPI_EEPROM();   //IP настройки

#ifdef  enable_twin_reset_to_restore_default_IP
//Для восстановления дефолтных настроек нужно нажать сброс в течение 1 секунды
    checkTwinReset();   //Проверка нажатия сброса 2 раза за 1 секунду - восстановление Default settings
#endif
    workSPI_EEPROM();
#ifdef enable_write_MAC
//Определяем в каком мы режиме - рабочем или технологическом
    if (HAL_GPIO_ReadPin(GPIOC, GPIO_PIN_4) == GPIO_PIN_SET){ //Технологический режим - сигнал выдает ПЛИС
//    if (HAL_GPIO_ReadPin(GPIOC, GPIO_PIN_4) == GPIO_PIN_RESET){ //Для отладки кода
        printf("write MAC Mode...\r\n");
        char tmp[18];
        char tmp2[2];

            /*HAL_StatusTypeDef result = */HAL_UART_Receive_IT(&huart6, (uint8_t*)tmp, 17);

            while (HAL_UART_GetState (&huart6) != HAL_UART_STATE_READY){
                blue_blink
                HAL_IWDG_Refresh(&hiwdg);
            };

        strncpy(tmp2, tmp, 2);
        macaddr[0] = convertHexToDecimal(tmp2);
        strncpy(tmp2, tmp+3, 2);
        macaddr[1] = convertHexToDecimal(tmp2);
        strncpy(tmp2, tmp+6, 2);
        macaddr[2] = convertHexToDecimal(tmp2);
        strncpy(tmp2, tmp+9, 2);
        macaddr[3] = convertHexToDecimal(tmp2);
        strncpy(tmp2, tmp+12, 2);
        macaddr[4] = convertHexToDecimal(tmp2);
        strncpy(tmp2, tmp+15, 2);
        macaddr[5] = convertHexToDecimal(tmp2);
        printf("new mac: %.2X:%.2X:%.2X:%.2X:%.2X:%.2X\n",macaddr[0],macaddr[1],macaddr[2],macaddr[3],macaddr[4],macaddr[5]);

        tmp[17]=0x00;
        int writeRes = BSP_EEPROM_WriteBuffer((uint8_t *)tmp, macAdressInEEPROM, 18);
        printf("mac write from UART in Hex to adress 0x%.4X on eprom: %d\r\n", macAdressInEEPROM, writeRes);

        while (1)
        {
            green_blink
            HAL_Delay(500);
            printf("wait new FPGA firmware\r\n");
            HAL_IWDG_Refresh(&hiwdg);
        }
    }
#endif

#ifndef   NEW_HTTP_SERVER
//    net_ini();
#endif

    net_ini_WIZNET(HTTP_SOCKET); //TCP socket 0

    //Выводим регистры Wiznet(
//    printWiznetReg();

  /* USER CODE END 2 */

  /* Infinite loop */
  /* USER CODE BEGIN WHILE */
    pingCheck();
    uint8_t udpSocket = UDP_SOCKET;
    prepearUDP_PLIS(udpSocket);

#ifdef   NEW_HTTP_SERVER //web serverWIZ
    uint8_t i;
    httpServer_init(TX_BUF_WEB, RX_BUF_WEB, MAX_HTTPSOCK, socknumlist);
    wep_define_func();
//    display_reg_webContent_list(); //Зарегистрированный web контент
#endif
    if (SEGGER){
//        SEGGER_RTT_ConfigUpBuffer(0, NULL, NULL, 0, SEGGER_RTT_MODE_BLOCK_IF_FIFO_FULL);//При отключении JLINK - блокируется MK
        SEGGER_RTT_SetTerminal(0); // Select terminal 0
        SEGGER_RTT_printf(0, "\r\nSystem Time: %d\r\n", HAL_GetTick()/1000);
        SEGGER_RTT_printf(0,RTT_CTRL_TEXT_BRIGHT_YELLOW);
        SEGGER_RTT_SetTerminal(1);
        SEGGER_RTT_printf(0,RTT_CTRL_TEXT_BRIGHT_GREEN);
        SEGGER_RTT_SetTerminal(2);
        SEGGER_RTT_printf(0,RTT_CTRL_TEXT_BRIGHT_CYAN);
        SEGGER_RTT_SetTerminal(3);
        SEGGER_RTT_printf(0,RTT_CTRL_TEXT_BRIGHT_GREEN);
        SEGGER_RTT_SetTerminal(4);
        SEGGER_RTT_printf(0,RTT_CTRL_TEXT_BRIGHT_GREEN);
        SEGGER_RTT_SetTerminal(6);
        SEGGER_RTT_printf(0,RTT_CTRL_TEXT_BRIGHT_RED);
        SEGGER_RTT_SetTerminal(0);
    }
    while (1)
    {
//HAL_GPIO_WritePin(GPIOD, DEBUG3_Pin, GPIO_PIN_SET);
//HAL_GPIO_WritePin(GPIOD, DEBUG3_Pin, GPIO_PIN_RESET);
#ifdef   NEW_HTTP_SERVER
        if ((UDP_or_TCP == TCP) && (startHttpTime + 300000 < HAL_GetTick())){
            printf("Long HTTP session - Reboot\r\n");
            reboot();
        }
        else{
            for(i = 0; i < MAX_HTTPSOCK; i++) {
                httpServer_run(i);
            }
        }

#endif
#ifndef   NEW_HTTP_SERVER
      net_poll();
#endif

      if (UDP_or_TCP == UDP)
      {
        if (HANDSHAKE == hanshakeON){
            sendReceiveUDP(udpSocket);
        }
        if (HANDSHAKE == hanshakeOFF)
            sendHANDSHAKE(udpSocket);
      } else {
          if (web == webON)
              HAL_IWDG_Refresh(&hiwdg);
      }
    /* USER CODE END WHILE */

    /* USER CODE BEGIN 3 */
//HAL_GPIO_WritePin(GPIOD, DEBUG3_Pin, GPIO_PIN_SET);
//HAL_GPIO_WritePin(GPIOD, DEBUG3_Pin, GPIO_PIN_RESET);
  }

  /* USER CODE END 3 */
}

void SystemClock_Config(void)
{
  RCC_OscInitTypeDef RCC_OscInitStruct = {0};
  RCC_ClkInitTypeDef RCC_ClkInitStruct = {0};

  /** Configure the main internal regulator output voltage
  */
  __HAL_RCC_PWR_CLK_ENABLE();
  __HAL_PWR_VOLTAGESCALING_CONFIG(PWR_REGULATOR_VOLTAGE_SCALE1);
  /** Initializes the RCC Oscillators according to the specified parameters
  * in the RCC_OscInitTypeDef structure.
  */
  RCC_OscInitStruct.OscillatorType = RCC_OSCILLATORTYPE_HSI|RCC_OSCILLATORTYPE_LSI;
  RCC_OscInitStruct.HSIState = RCC_HSI_ON;
  RCC_OscInitStruct.HSICalibrationValue = RCC_HSICALIBRATION_DEFAULT;
  RCC_OscInitStruct.LSIState = RCC_LSI_ON;
  RCC_OscInitStruct.PLL.PLLState = RCC_PLL_ON;
  RCC_OscInitStruct.PLL.PLLSource = RCC_PLLSOURCE_HSI;
  RCC_OscInitStruct.PLL.PLLM = 8;
  RCC_OscInitStruct.PLL.PLLN = 168;
  RCC_OscInitStruct.PLL.PLLP = RCC_PLLP_DIV2;
  RCC_OscInitStruct.PLL.PLLQ = 7;
  if (HAL_RCC_OscConfig(&RCC_OscInitStruct) != HAL_OK)
  {
    Error_Handler();
  }
  /** Initializes the CPU, AHB and APB buses clocks
  */
  RCC_ClkInitStruct.ClockType = RCC_CLOCKTYPE_HCLK|RCC_CLOCKTYPE_SYSCLK
                              |RCC_CLOCKTYPE_PCLK1|RCC_CLOCKTYPE_PCLK2;
  RCC_ClkInitStruct.SYSCLKSource = RCC_SYSCLKSOURCE_PLLCLK;
  RCC_ClkInitStruct.AHBCLKDivider = RCC_SYSCLK_DIV1;
  RCC_ClkInitStruct.APB1CLKDivider = RCC_HCLK_DIV4;
  RCC_ClkInitStruct.APB2CLKDivider = RCC_HCLK_DIV2;

  if (HAL_RCC_ClockConfig(&RCC_ClkInitStruct, FLASH_LATENCY_5) != HAL_OK)
  {
    Error_Handler();
  }
}

static void MX_CRC_Init(void)
{

  hcrc.Instance = CRC;
  if (HAL_CRC_Init(&hcrc) != HAL_OK)
  {
    Error_Handler();
  }

}

static void MX_I2C1_Init(void)
{

  hi2c1.Instance = I2C1;
  hi2c1.Init.ClockSpeed = 400000;
  hi2c1.Init.DutyCycle = I2C_DUTYCYCLE_2;
  hi2c1.Init.OwnAddress1 = 0;
  hi2c1.Init.AddressingMode = I2C_ADDRESSINGMODE_7BIT;
  hi2c1.Init.DualAddressMode = I2C_DUALADDRESS_DISABLE;
  hi2c1.Init.OwnAddress2 = 0;
  hi2c1.Init.GeneralCallMode = I2C_GENERALCALL_DISABLE;
  hi2c1.Init.NoStretchMode = I2C_NOSTRETCH_DISABLE;
  if (HAL_I2C_Init(&hi2c1) != HAL_OK)
  {
    Error_Handler();
  }

}

static void MX_I2C2_Init(void)
{

  hi2c2.Instance = I2C2;
  hi2c2.Init.ClockSpeed = 100000;
  hi2c2.Init.DutyCycle = I2C_DUTYCYCLE_2;
  hi2c2.Init.OwnAddress1 = 0;
  hi2c2.Init.AddressingMode = I2C_ADDRESSINGMODE_7BIT;
  hi2c2.Init.DualAddressMode = I2C_DUALADDRESS_DISABLE;
  hi2c2.Init.OwnAddress2 = 0;
  hi2c2.Init.GeneralCallMode = I2C_GENERALCALL_DISABLE;
  hi2c2.Init.NoStretchMode = I2C_NOSTRETCH_DISABLE;
  if (HAL_I2C_Init(&hi2c2) != HAL_OK)
  {
    Error_Handler();
  }

}

static void MX_IWDG_Init(void)
{

  hiwdg.Instance = IWDG;
  hiwdg.Init.Prescaler = IWDG_PRESCALER_128;
  hiwdg.Init.Reload = 2000;
  if (HAL_IWDG_Init(&hiwdg) != HAL_OK)
  {
    Error_Handler();
  }

}

static void MX_RNG_Init(void)
{

  hrng.Instance = RNG;
  if (HAL_RNG_Init(&hrng) != HAL_OK)
  {
    Error_Handler();
  }

}

static void MX_RTC_Init(void)
{

  RTC_TimeTypeDef sTime = {0};
  RTC_DateTypeDef sDate = {0};

  /** Initialize RTC Only
  */
  hrtc.Instance = RTC;
  hrtc.Init.HourFormat = RTC_HOURFORMAT_24;
  hrtc.Init.AsynchPrediv = 127;
  hrtc.Init.SynchPrediv = 255;
  hrtc.Init.OutPut = RTC_OUTPUT_DISABLE;
  hrtc.Init.OutPutPolarity = RTC_OUTPUT_POLARITY_HIGH;
  hrtc.Init.OutPutType = RTC_OUTPUT_TYPE_OPENDRAIN;
  if (HAL_RTC_Init(&hrtc) != HAL_OK)
  {
    Error_Handler();
  }

  /** Initialize RTC and set the Time and Date
  */
  sTime.Hours = 0x0;
  sTime.Minutes = 0x0;
  sTime.Seconds = 0x0;
  sTime.DayLightSaving = RTC_DAYLIGHTSAVING_NONE;
  sTime.StoreOperation = RTC_STOREOPERATION_RESET;
  if (HAL_RTC_SetTime(&hrtc, &sTime, RTC_FORMAT_BCD) != HAL_OK)
  {
    Error_Handler();
  }
  sDate.WeekDay = RTC_WEEKDAY_MONDAY;
  sDate.Month = RTC_MONTH_MAY;
  sDate.Date = 0x9;
  sDate.Year = 0x23;

  if (HAL_RTC_SetDate(&hrtc, &sDate, RTC_FORMAT_BCD) != HAL_OK)
  {
    Error_Handler();
  }

}

static void MX_SPI1_Init(void)
{

  /* SPI1 parameter configuration*/
  hspi1.Instance = SPI1;
  hspi1.Init.Mode = SPI_MODE_MASTER;
  hspi1.Init.Direction = SPI_DIRECTION_2LINES;
  hspi1.Init.DataSize = SPI_DATASIZE_8BIT;
  hspi1.Init.CLKPolarity = SPI_POLARITY_LOW;
  hspi1.Init.CLKPhase = SPI_PHASE_1EDGE;
  hspi1.Init.NSS = SPI_NSS_SOFT;
  hspi1.Init.BaudRatePrescaler = SPI_BAUDRATEPRESCALER_8;
  hspi1.Init.FirstBit = SPI_FIRSTBIT_MSB;
  hspi1.Init.TIMode = SPI_TIMODE_DISABLE;
  hspi1.Init.CRCCalculation = SPI_CRCCALCULATION_DISABLE;
  hspi1.Init.CRCPolynomial = 10;
  if (HAL_SPI_Init(&hspi1) != HAL_OK)
  {
    Error_Handler();
  }

}

static void MX_SPI2_Init(void)
{

  /* SPI2 parameter configuration*/
  hspi2.Instance = SPI2;
  hspi2.Init.Mode = SPI_MODE_MASTER;
  hspi2.Init.Direction = SPI_DIRECTION_2LINES;
  hspi2.Init.DataSize = SPI_DATASIZE_8BIT;
  hspi2.Init.CLKPolarity = SPI_POLARITY_LOW;
  hspi2.Init.CLKPhase = SPI_PHASE_2EDGE;
  hspi2.Init.NSS = SPI_NSS_SOFT;
  hspi2.Init.BaudRatePrescaler = SPI_BAUDRATEPRESCALER_4;
  hspi2.Init.FirstBit = SPI_FIRSTBIT_MSB;
  hspi2.Init.TIMode = SPI_TIMODE_DISABLE;
  hspi2.Init.CRCCalculation = SPI_CRCCALCULATION_DISABLE;
  hspi2.Init.CRCPolynomial = 10;
  if (HAL_SPI_Init(&hspi2) != HAL_OK)
  {
    Error_Handler();
  }

}

static void MX_SPI3_Init(void)
{

  /* SPI3 parameter configuration*/
  hspi3.Instance = SPI3;
  hspi3.Init.Mode = SPI_MODE_MASTER;
  hspi3.Init.Direction = SPI_DIRECTION_2LINES;
  hspi3.Init.DataSize = SPI_DATASIZE_8BIT;
  hspi3.Init.CLKPolarity = SPI_POLARITY_LOW;
  hspi3.Init.CLKPhase = SPI_PHASE_1EDGE;
  hspi3.Init.NSS = SPI_NSS_SOFT;
  hspi3.Init.BaudRatePrescaler = SPI_BAUDRATEPRESCALER_8;
  hspi3.Init.FirstBit = SPI_FIRSTBIT_MSB;
  hspi3.Init.TIMode = SPI_TIMODE_DISABLE;
  hspi3.Init.CRCCalculation = SPI_CRCCALCULATION_DISABLE;
  hspi3.Init.CRCPolynomial = 10;
  if (HAL_SPI_Init(&hspi3) != HAL_OK)
  {
    Error_Handler();
  }

}

static void MX_USART2_UART_Init(void)
{

  huart2.Instance = USART2;
  huart2.Init.BaudRate = 115200;
  huart2.Init.WordLength = UART_WORDLENGTH_8B;
  huart2.Init.StopBits = UART_STOPBITS_1;
  huart2.Init.Parity = UART_PARITY_NONE;
  huart2.Init.Mode = UART_MODE_TX_RX;
  huart2.Init.HwFlowCtl = UART_HWCONTROL_NONE;
  huart2.Init.OverSampling = UART_OVERSAMPLING_16;
  if (HAL_UART_Init(&huart2) != HAL_OK)
  {
    Error_Handler();
  }

}

static void MX_USART6_UART_Init(void)
{

  huart6.Instance = USART6;
  huart6.Init.BaudRate = 115200;
  huart6.Init.WordLength = UART_WORDLENGTH_8B;
  huart6.Init.StopBits = UART_STOPBITS_1;
  huart6.Init.Parity = UART_PARITY_NONE;
  huart6.Init.Mode = UART_MODE_TX_RX;
  huart6.Init.HwFlowCtl = UART_HWCONTROL_NONE;
  huart6.Init.OverSampling = UART_OVERSAMPLING_16;
  if (HAL_UART_Init(&huart6) != HAL_OK)
  {
    Error_Handler();
  }

}

static void MX_DMA_Init(void)
{

  /* DMA controller clock enable */
  __HAL_RCC_DMA2_CLK_ENABLE();

  /* DMA interrupt init */
  /* DMA2_Stream0_IRQn interrupt configuration */
  HAL_NVIC_SetPriority(DMA2_Stream0_IRQn, 0, 0);
  HAL_NVIC_EnableIRQ(DMA2_Stream0_IRQn);
  /* DMA2_Stream3_IRQn interrupt configuration */
  HAL_NVIC_SetPriority(DMA2_Stream3_IRQn, 0, 0);
  HAL_NVIC_EnableIRQ(DMA2_Stream3_IRQn);
  /* DMA2_Stream6_IRQn interrupt configuration */
  HAL_NVIC_SetPriority(DMA2_Stream6_IRQn, 0, 0);
  HAL_NVIC_EnableIRQ(DMA2_Stream6_IRQn);

}

static void MX_GPIO_Init(void)
{
  GPIO_InitTypeDef GPIO_InitStruct = {0};

  /* GPIO Ports Clock Enable */
  __HAL_RCC_GPIOE_CLK_ENABLE();
  __HAL_RCC_GPIOH_CLK_ENABLE();
  __HAL_RCC_GPIOC_CLK_ENABLE();
  __HAL_RCC_GPIOA_CLK_ENABLE();
  __HAL_RCC_GPIOB_CLK_ENABLE();
  __HAL_RCC_GPIOD_CLK_ENABLE();

  /*Configure GPIO pin Output Level */
  HAL_GPIO_WritePin(GPIOE, CS_EEPROM_Pin|HOLD_EEPROM_Pin, GPIO_PIN_SET);

  /*Configure GPIO pin Output Level */
  HAL_GPIO_WritePin(GPIOE, GPIO_PIN_3|GPIO_PIN_4, GPIO_PIN_RESET);

  /*Configure GPIO pin Output Level */
  HAL_GPIO_WritePin(GPIOC, OTG_FS_PowerSwitchOn_Pin|GPIO_PIN_9, GPIO_PIN_SET);

  /*Configure GPIO pin Output Level */
  HAL_GPIO_WritePin(GPIOC, GPIO_PIN_5, GPIO_PIN_RESET);

  /*Configure GPIO pin Output Level */
  HAL_GPIO_WritePin(GPIOB, GPIO_PIN_12, GPIO_PIN_RESET);

  /*Configure GPIO pin Output Level */
  HAL_GPIO_WritePin(GPIOD, GPIO_PIN_9|GPIO_PIN_10|Green_Led_Pin|Orange_Led_Pin
                          |Red_Led_Pin|Blue_Led_Pin|GPIO_PIN_0|GPIO_PIN_1
                          |DEBUG1_Pin|DEBUG2_Pin|DEBUG3_Pin|GPIO_PIN_6
                          |GPIO_PIN_7, GPIO_PIN_RESET);

  /*Configure GPIO pin Output Level */
  HAL_GPIO_WritePin(GPIOD, GPIO_PIN_11|GPIO_PIN_2, GPIO_PIN_SET);

  /*Configure GPIO pin Output Level */
  HAL_GPIO_WritePin(GPIOA, GPIO_PIN_8, GPIO_PIN_SET);

  /*Configure GPIO pin : CS_EEPROM_Pin */
  GPIO_InitStruct.Pin = CS_EEPROM_Pin;
  GPIO_InitStruct.Mode = GPIO_MODE_OUTPUT_PP;
  GPIO_InitStruct.Pull = GPIO_PULLUP;
  GPIO_InitStruct.Speed = GPIO_SPEED_FREQ_MEDIUM;
  HAL_GPIO_Init(CS_EEPROM_GPIO_Port, &GPIO_InitStruct);

  /*Configure GPIO pins : PE3 PE4 HOLD_EEPROM_Pin */
  GPIO_InitStruct.Pin = GPIO_PIN_3|GPIO_PIN_4|HOLD_EEPROM_Pin;
  GPIO_InitStruct.Mode = GPIO_MODE_OUTPUT_PP;
  GPIO_InitStruct.Pull = GPIO_NOPULL;
  GPIO_InitStruct.Speed = GPIO_SPEED_FREQ_LOW;
  HAL_GPIO_Init(GPIOE, &GPIO_InitStruct);

  /*Configure GPIO pins : OTG_FS_PowerSwitchOn_Pin PC5 */
  GPIO_InitStruct.Pin = OTG_FS_PowerSwitchOn_Pin|GPIO_PIN_5;
  GPIO_InitStruct.Mode = GPIO_MODE_OUTPUT_PP;
  GPIO_InitStruct.Pull = GPIO_NOPULL;
  GPIO_InitStruct.Speed = GPIO_SPEED_FREQ_LOW;
  HAL_GPIO_Init(GPIOC, &GPIO_InitStruct);

  /*Configure GPIO pins : write_MAC_Pin PC8 */
  GPIO_InitStruct.Pin = write_MAC_Pin|GPIO_PIN_8;
  GPIO_InitStruct.Mode = GPIO_MODE_INPUT;
  GPIO_InitStruct.Pull = GPIO_NOPULL;
  HAL_GPIO_Init(GPIOC, &GPIO_InitStruct);

  /*Configure GPIO pin : PB2 */
  GPIO_InitStruct.Pin = GPIO_PIN_2;
  GPIO_InitStruct.Mode = GPIO_MODE_INPUT;
  GPIO_InitStruct.Pull = GPIO_NOPULL;
  HAL_GPIO_Init(GPIOB, &GPIO_InitStruct);

  /*Configure GPIO pin : PB12 */
  GPIO_InitStruct.Pin = GPIO_PIN_12;
  GPIO_InitStruct.Mode = GPIO_MODE_OUTPUT_PP;
  GPIO_InitStruct.Pull = GPIO_NOPULL;
  GPIO_InitStruct.Speed = GPIO_SPEED_FREQ_LOW;
  HAL_GPIO_Init(GPIOB, &GPIO_InitStruct);

  /*Configure GPIO pin : PB14 */
  GPIO_InitStruct.Pin = GPIO_PIN_14;
  GPIO_InitStruct.Mode = GPIO_MODE_INPUT;
  GPIO_InitStruct.Pull = GPIO_PULLDOWN;
  HAL_GPIO_Init(GPIOB, &GPIO_InitStruct);

  /*Configure GPIO pin : PB15 */
  GPIO_InitStruct.Pin = GPIO_PIN_15;
  GPIO_InitStruct.Mode = GPIO_MODE_IT_RISING;
  GPIO_InitStruct.Pull = GPIO_NOPULL;
  HAL_GPIO_Init(GPIOB, &GPIO_InitStruct);

  /*Configure GPIO pin : INT_Pin */
  GPIO_InitStruct.Pin = INT_Pin;
  GPIO_InitStruct.Mode = GPIO_MODE_INPUT;
  GPIO_InitStruct.Pull = GPIO_NOPULL;
  HAL_GPIO_Init(INT_GPIO_Port, &GPIO_InitStruct);

  /*Configure GPIO pins : PD9 PD10 PD11 Green_Led_Pin
                           Orange_Led_Pin Red_Led_Pin Blue_Led_Pin PD0
                           PD1 DEBUG1_Pin DEBUG2_Pin DEBUG3_Pin
                           PD7 */
  GPIO_InitStruct.Pin = GPIO_PIN_9|GPIO_PIN_10|GPIO_PIN_11|Green_Led_Pin
                          |Orange_Led_Pin|Red_Led_Pin|Blue_Led_Pin|GPIO_PIN_0
                          |GPIO_PIN_1|DEBUG1_Pin|DEBUG2_Pin|DEBUG3_Pin
                          |GPIO_PIN_7;
  GPIO_InitStruct.Mode = GPIO_MODE_OUTPUT_PP;
  GPIO_InitStruct.Pull = GPIO_NOPULL;
  GPIO_InitStruct.Speed = GPIO_SPEED_FREQ_VERY_HIGH;
  HAL_GPIO_Init(GPIOD, &GPIO_InitStruct);

  /*Configure GPIO pin : PC9 */
  GPIO_InitStruct.Pin = GPIO_PIN_9;
  GPIO_InitStruct.Mode = GPIO_MODE_OUTPUT_PP;
  GPIO_InitStruct.Pull = GPIO_NOPULL;
  GPIO_InitStruct.Speed = GPIO_SPEED_FREQ_VERY_HIGH;
  HAL_GPIO_Init(GPIOC, &GPIO_InitStruct);

  /*Configure GPIO pin : PA8 */
  GPIO_InitStruct.Pin = GPIO_PIN_8;
  GPIO_InitStruct.Mode = GPIO_MODE_OUTPUT_PP;
  GPIO_InitStruct.Pull = GPIO_NOPULL;
  GPIO_InitStruct.Speed = GPIO_SPEED_FREQ_VERY_HIGH;
  HAL_GPIO_Init(GPIOA, &GPIO_InitStruct);

  /*Configure GPIO pin : PD2 */
  GPIO_InitStruct.Pin = GPIO_PIN_2;
  GPIO_InitStruct.Mode = GPIO_MODE_OUTPUT_PP;
  GPIO_InitStruct.Pull = GPIO_PULLUP;
  GPIO_InitStruct.Speed = GPIO_SPEED_FREQ_MEDIUM;
  HAL_GPIO_Init(GPIOD, &GPIO_InitStruct);

  /*Configure GPIO pin : PD6 */
  GPIO_InitStruct.Pin = GPIO_PIN_6;
  GPIO_InitStruct.Mode = GPIO_MODE_OUTPUT_PP;
  GPIO_InitStruct.Pull = GPIO_NOPULL;
  GPIO_InitStruct.Speed = GPIO_SPEED_FREQ_LOW;
  HAL_GPIO_Init(GPIOD, &GPIO_InitStruct);

  /* EXTI interrupt init*/
  HAL_NVIC_SetPriority(EXTI15_10_IRQn, 0, 0);
  HAL_NVIC_EnableIRQ(EXTI15_10_IRQn);

}

/* USER CODE BEGIN 4 */

static void MX_IWDG_Init_abonent(void)
{
  hiwdg.Instance = IWDG;
  hiwdg.Init.Prescaler = IWDG_PRESCALER_256;
//  hiwdg.Init.Reload = 6000; //17 секунд
  hiwdg.Init.Reload = 7000; //26 секунд
  if (HAL_IWDG_Init(&hiwdg) != HAL_OK)
  {
    Error_Handler();
  }
}
static void MX_IWDG_Init_base(void)
{
  hiwdg.Instance = IWDG;
  hiwdg.Init.Prescaler = IWDG_PRESCALER_256;
  hiwdg.Init.Reload = 6500; //22 секунды
  if (HAL_IWDG_Init(&hiwdg) != HAL_OK)
  {
    Error_Handler();
  }
}

void sendPackets(uint8_t sn, uint8_t* destip, uint16_t destport)
{
    HAL_GPIO_WritePin(GPIOD, DEBUG1_Pin, GPIO_PIN_SET);
    if (ABONENT_or_BASE == BASE) {

#ifdef baseSendTestData
        sendto(sn, (uint8_t *)TEST_DATA, MAX_PACKET_LEN, destip, destport);
#endif
#ifndef baseSendTestData
#ifdef enable_BUFFER_FIFO
        strncpy((char *)dataFromBase, bufDataFromBase + MAX_PACKET_LEN * indexSendBufData, MAX_PACKET_LEN );
        ++indexSendBufData;
        if (indexSendBufData == BUF_PACKET_SIZE)
            indexSendBufData = 0;
#endif
        // Перед отправкой конверсия данных
        convertToAbonData();
#ifndef enable_smallBUFFER
        sendto(sn, (uint8_t *)dataFromBase, MAX_PACKET_LEN, destip, destport);
#endif
#ifdef enable_smallBUFFER
        strncpy((char *)(smallBufDataFromBase + smallBufDataFromBaseIndex * MAX_PACKET_LEN),
                (const char*)dataFromBase, MAX_PACKET_LEN);
        ++smallBufDataFromBaseIndex;
        if (smallBufDataFromBaseIndex == SMALL_BUFF_SIZE){
            sendto(sn, (uint8_t *)smallBufDataFromBase, MAX_PACKET_LEN * SMALL_BUFF_SIZE, destip, destport);
            smallBufDataFromBaseIndex = 0;
        }
#endif

#endif
    }
    if (ABONENT_or_BASE == ABONENT) {
#ifdef abonSendTestData
        sendto(sn, (uint8_t *)TEST_DATA, MAX_PACKET_LEN, destip, destport);
#endif
#ifndef abonSendTestData
#ifdef enable_BUFFER_FIFO
// Если раскомментировать то все ломается - буфер только на базе
//        strncpy((char *)dataFromDx, bufDataFromAbon + MAX_PACKET_LEN * indexSendBufData, MAX_PACKET_LEN );
//        ++indexSendBufData;
//        if (indexSendBufData == BUF_PACKET_SIZE)
//            indexSendBufData = 0;
#endif
        //После обмена с ПЛИС конверсия данных
        convertToBaseData();
        sendto(sn, (uint8_t *)dataFromDx, MAX_PACKET_LEN, destip, destport);
#endif
    }

    HAL_GPIO_WritePin(GPIOD, DEBUG1_Pin, GPIO_PIN_RESET);
#ifdef   enable_BIG_PACKET
    indicateSend(1, 2);
#endif
#ifndef   enable_BIG_PACKET
    indicateSend(20, 40);
#endif
}

void receivePackets(uint8_t sn, uint8_t* destip, uint16_t destport)
{
    HAL_GPIO_WritePin(GPIOB, GPIO_PIN_12, GPIO_PIN_SET); //Сигнал в ПЛИС
    HAL_GPIO_WritePin(GPIOD, DEBUG2_Pin, GPIO_PIN_SET); //Логический анализатор
    uint32_t currTime = HAL_GetTick();
    ++num_rcvd_SEGGER;

    if (ABONENT_or_BASE == ABONENT) {
#ifdef enable_SKIP_Packets
        if ((currTime > 20000) && (num_rcvd_SEGGER % 7000 == 0)){ //Пропуск пакета возможен после 20 секунд работы раз в 10 секунд
            if(nextPacketSkip == 1){
                nextPacketSkip = 0;
                printf_DMA("************************* packet %d, System time %dd %dh %dm %ds \r\n",
                           num_rcvd_SEGGER,
                           currTime/(24 * 3600000),
                           (currTime/3600000) % 24,
                           (currTime/60000) % 60,
                           (currTime/1000) % 60);
                if (SEGGER){
                    SEGGER_RTT_SetTerminal(0);
                    SEGGER_RTT_printf(0, "************************* packet %d, System time %dd %dh %dm %ds \r\n",
                                      num_rcvd_SEGGER,
                                      currTime/(24 * 3600000),
                                      (currTime/3600000) % 24,
                                      (currTime/60000) % 60,
                                      (currTime/1000) % 60);
                }
                HAL_GPIO_WritePin(GPIOB, GPIO_PIN_12, GPIO_PIN_RESET); //Сигнал в ПЛИС
                return;
            }
        }
#endif
        if (num_rcvd_SEGGER % 120000 == 0) { //каждые 3 минуты - диагностическое сообщение
            printf_DMA("Abonent received packet %d, System time %dd %dh %dm %ds \r\n",
                       num_rcvd_SEGGER,
                       currTime/(24 * 3600000),
                       (currTime/3600000) % 24,
                       (currTime/60000) % 60,
                       (currTime/1000) % 60);
        }

#ifndef enable_smallBUFFER
        recvfrom(sn, (uint8_t *)dataToDx, MAX_PACKET_LEN, destip, &destport);
#endif
#ifdef enable_smallBUFFER
        if (smallBufDataToDxIndex == SMALL_BUFF_SIZE){
            recvfrom(sn, (uint8_t *)smallBufDataToDx, MAX_PACKET_LEN * SMALL_BUFF_SIZE, destip, &destport);
            strncpy((char *)dataToDx, (const char*)smallBufDataToDx , MAX_PACKET_LEN);
            smallBufDataToDxIndex = 1;
        }
        else {
            strncpy((char *)dataToDx,
                    (const char*)smallBufDataToDx + smallBufDataToDxIndex * MAX_PACKET_LEN, MAX_PACKET_LEN);
            ++smallBufDataToDxIndex;
        }
#endif

        if (REBOOT == checkCommands(dataToDx)){
            red_blink  red_blink  red_blink
                printf("Received command Reboot from Base\r\n");
            reboot();
        }
        //        if (NET_DIAGNOSTIC == checkCommands(dataToDx)){
        //            red_blink  red_blink  red_blink
        //            printf("Received command Net Diagnostic from Base\r\n");
        //            //Записываем флаг диагностики в EEPROM
        //            uint8_t netDiagnostic[1];
        //            netDiagnostic[0] = 0x88;
        //            EEPROM_SPI_WriteBuffer(netDiagnostic, netDiagnosticFlag, 1);
        //            printf("netDiagnosticFlag set ON\r\n");
        //            reboot();
        //        }
    }

    if (ABONENT_or_BASE == BASE) {
        if (num_rcvd_SEGGER % 120000 == 0) { //каждые 3 минуты - диагностическое сообщение
            printf_DMA("Base received packet %d, System time %dd %dh %dm %ds \r\n",
                       num_rcvd_SEGGER,
                       currTime/(24 * 3600000),
                       (currTime/3600000) % 24,
                       (currTime/60000) % 60,
                       (currTime/1000) % 60);
        }
        recvfrom(sn, (uint8_t *)dataToBase, MAX_PACKET_LEN, destip, &destport);
    }

#ifdef   enable_BIG_PACKET
    indicateReceive(1, 2);
#endif
#ifndef   enable_BIG_PACKET
    indicateReceive(20, 40);
#endif

#ifdef enable_SKIP_Packets
    if (HAL_GPIO_ReadPin(GPIOB, GPIO_PIN_14) == GPIO_PIN_SET){
        nextPacketSkip = 1;
    }
#endif
    HAL_GPIO_WritePin(GPIOD, DEBUG2_Pin, GPIO_PIN_RESET);
    HAL_GPIO_WritePin(GPIOB, GPIO_PIN_12, GPIO_PIN_RESET); //Сигнал в ПЛИС
}

int convertHexToDecimal(char hexadecimalnumber[2])
{
    int decimalNumber = 0;
    char hexDigits[16] = {'0','1','2','3','4','5','6','7','8','9','A','B','C','D','E','F'};
    for ( int j = 0; j < 16; j++)
    {
       if (hexadecimalnumber[0] == hexDigits[j])
           decimalNumber += j * 16;
    }
    for (int j = 0; j < 16; j++)
    {
       if (hexadecimalnumber[1] == hexDigits[j])
           decimalNumber += j;
    }
//    printf("Decimal Number : %d", decimalNumber);
    return decimalNumber;
}
//    HAL_SPI_TransmitReceive(&hspi2, test1 , rxCyclon, MAX_PACKET_LEN, 0x1000);
//    printf("%u\trxCyclon - "
//         "%.2X%.2X%.2X%.2X%.2X%.2X%.2X%.2X"
//         "%.2X%.2X%.2X%.2X%.2X%.2X%.2X%.2X"
//         "%.2X%.2X%.2X%.2X%.2X%.2X%.2X%.2X"
//         "%.2X%.2X%.2X%.2X%.2X%.2X%.2X%.2X"
//         "%.2X%.2X%.2X%.2X%.2X%.2X%.2X%.2X"
//         "%.2X%.2X%.2X%.2X%.2X%.2X%.2X%.2X"
//         "\r\n",
//         HAL_GetTick(),
//          rxCyclon[0],rxCyclon[1],rxCyclon[2],rxCyclon[3],rxCyclon[4],rxCyclon[5],rxCyclon[6],rxCyclon[7],
//          rxCyclon[8],rxCyclon[9],rxCyclon[10],rxCyclon[11],rxCyclon[12],rxCyclon[13],rxCyclon[14],rxCyclon[15],
//          rxCyclon[16],rxCyclon[17],rxCyclon[18],rxCyclon[19],rxCyclon[20],rxCyclon[21],rxCyclon[22],rxCyclon[23],
//          rxCyclon[24],rxCyclon[25],rxCyclon[26],rxCyclon[27],rxCyclon[28],rxCyclon[29],rxCyclon[30],rxCyclon[31],
//          rxCyclon[32],rxCyclon[33],rxCyclon[34],rxCyclon[35],rxCyclon[36],rxCyclon[37],rxCyclon[38],rxCyclon[39],
//          rxCyclon[40],rxCyclon[41],rxCyclon[42],rxCyclon[43],rxCyclon[44],rxCyclon[45],rxCyclon[46],rxCyclon[47]
//          );
//    printf("\ttxCyclon - "
//         "%.2X%.2X%.2X%.2X%.2X%.2X%.2X%.2X"
//         "%.2X%.2X%.2X%.2X%.2X%.2X%.2X%.2X"
//         "%.2X%.2X%.2X%.2X%.2X%.2X%.2X%.2X"
//         "%.2X%.2X%.2X%.2X%.2X%.2X%.2X%.2X"
//         "%.2X%.2X%.2X%.2X%.2X%.2X%.2X%.2X"
//         "%.2X%.2X%.2X%.2X%.2X%.2X%.2X%.2X"
//         "\r\n",
//          test1[0],test1[1],test1[2],test1[3],test1[4],test1[5],test1[6],test1[7],
//          test1[8],test1[9],test1[10],test1[11],test1[12],test1[13],test1[14],test1[15],
//          test1[16],test1[17],test1[18],test1[19],test1[20],test1[21],test1[22],test1[23],
//          test1[24],test1[25],test1[26],test1[27],test1[28],test1[29],test1[30],test1[31],
//          test1[32],test1[33],test1[34],test1[35],test1[36],test1[37],test1[38],test1[39],
//          test1[40],test1[41],test1[42],test1[43],test1[44],test1[45],test1[46],test1[47]
//          );

//     if(strcmp((char*)rxCyclon, (char*)zeroStr) != 0)
//         printf("string no zero\r\n");
/* USER CODE END 4 */

void Error_Handler(void)
{
  /* USER CODE BEGIN Error_Handler_Debug */
  /* User can add his own implementation to report the HAL error return state */
  __disable_irq();
  while (1)
  {
      red_blink
  }
  /* USER CODE END Error_Handler_Debug */
}
